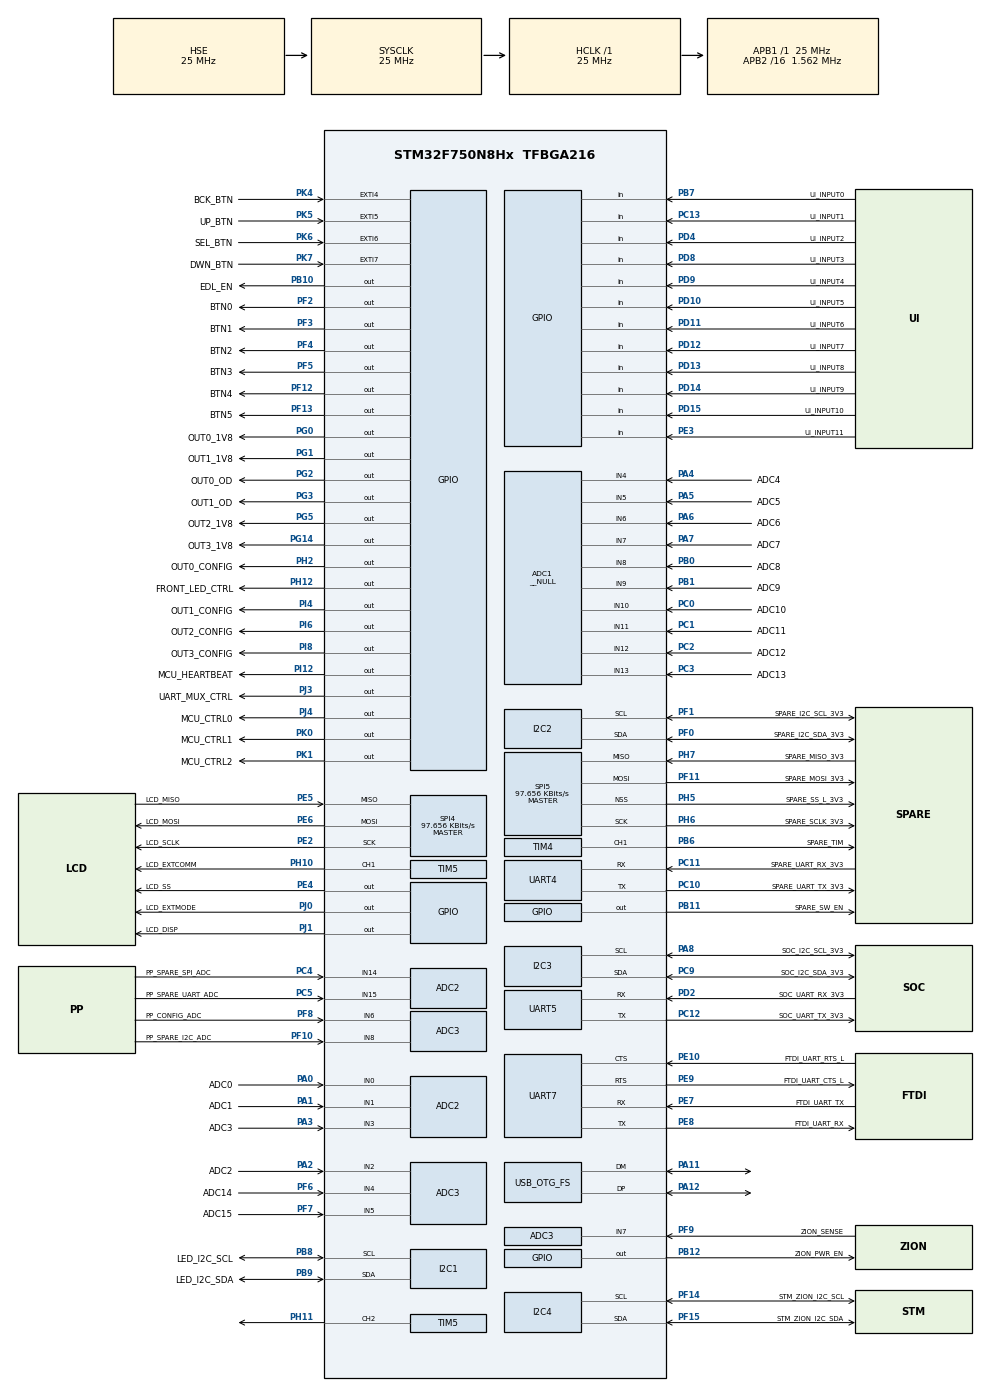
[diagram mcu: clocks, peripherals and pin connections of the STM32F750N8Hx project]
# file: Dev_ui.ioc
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ADC1.Channel-0\#ChannelRegularConversion=ADC_CHANNEL_3
ADC1.Channel-1\#ChannelRegularConversion=ADC_CHANNEL_4
ADC1.Channel-10\#ChannelRegularConversion=ADC_CHANNEL_13
ADC1.Channel-2\#ChannelRegularConversion=ADC_CHANNEL_5
ADC1.Channel-3\#ChannelRegularConversion=ADC_CHANNEL_6
ADC1.Channel-4\#ChannelRegularConversion=ADC_CHANNEL_7
ADC1.Channel-5\#ChannelRegularConversion=ADC_CHANNEL_8
ADC1.Channel-6\#ChannelRegularConversion=ADC_CHANNEL_9
ADC1.Channel-7\#ChannelRegularConversion=ADC_CHANNEL_10
ADC1.Channel-8\#ChannelRegularConversion=ADC_CHANNEL_11
ADC1.Channel-9\#ChannelRegularConversion=ADC_CHANNEL_12
ADC1.ContinuousConvMode=ENABLE
ADC1.DMAContinuousRequests=ENABLE
ADC1.InjNumberOfConversion=0
ADC1.Mode=__NULL
ADC1.NbrOfConversion=11
ADC1.NbrOfConversionFlag=1
ADC1.Rank-0\#ChannelRegularConversion=1
ADC1.Rank-1\#ChannelRegularConversion=2
ADC1.Rank-10\#ChannelRegularConversion=11
ADC1.Rank-2\#ChannelRegularConversion=3
ADC1.Rank-3\#ChannelRegularConversion=4
ADC1.Rank-4\#ChannelRegularConversion=5
ADC1.Rank-5\#ChannelRegularConversion=6
ADC1.Rank-6\#ChannelRegularConversion=7
ADC1.Rank-7\#ChannelRegularConversion=8
ADC1.Rank-8\#ChannelRegularConversion=9
ADC1.Rank-9\#ChannelRegularConversion=10
ADC1.SamplingTime-0\#ChannelRegularConversion=ADC_SAMPLETIME_480CYCLES
ADC1.SamplingTime-1\#ChannelRegularConversion=ADC_SAMPLETIME_480CYCLES
ADC1.SamplingTime-10\#ChannelRegularConversion=ADC_SAMPLETIME_480CYCLES
ADC1.SamplingTime-2\#ChannelRegularConversion=ADC_SAMPLETIME_480CYCLES
ADC1.SamplingTime-3\#ChannelRegularConversion=ADC_SAMPLETIME_480CYCLES
ADC1.SamplingTime-4\#ChannelRegularConversion=ADC_SAMPLETIME_480CYCLES
ADC1.SamplingTime-5\#ChannelRegularConversion=ADC_SAMPLETIME_480CYCLES
ADC1.SamplingTime-6\#ChannelRegularConversion=ADC_SAMPLETIME_480CYCLES
ADC1.SamplingTime-7\#ChannelRegularConversion=ADC_SAMPLETIME_480CYCLES
ADC1.SamplingTime-8\#ChannelRegularConversion=ADC_SAMPLETIME_480CYCLES
ADC1.SamplingTime-9\#ChannelRegularConversion=ADC_SAMPLETIME_480CYCLES
ADC1.ScanConvMode=ADC_SCAN_ENABLE
ADC1.master=1
ADC2.Channel-0\#ChannelRegularConversion=ADC_CHANNEL_0
ADC2.Channel-1\#ChannelRegularConversion=ADC_CHANNEL_1
ADC2.Channel-2\#ChannelRegularConversion=ADC_CHANNEL_14
ADC2.Channel-3\#ChannelRegularConversion=ADC_CHANNEL_15
ADC2.ContinuousConvMode=ENABLE
ADC2.DMAContinuousRequests=ENABLE
ADC2.NbrOfConversion=4
ADC2.NbrOfConversionFlag=1
ADC2.Rank-0\#ChannelRegularConversion=1
ADC2.Rank-1\#ChannelRegularConversion=2
ADC2.Rank-2\#ChannelRegularConversion=3
ADC2.Rank-3\#ChannelRegularConversion=4
ADC2.SamplingTime-0\#ChannelRegularConversion=ADC_SAMPLETIME_480CYCLES
ADC2.SamplingTime-1\#ChannelRegularConversion=ADC_SAMPLETIME_480CYCLES
ADC2.SamplingTime-2\#ChannelRegularConversion=ADC_SAMPLETIME_480CYCLES
ADC2.SamplingTime-3\#ChannelRegularConversion=ADC_SAMPLETIME_480CYCLES
ADC2.ScanConvMode=ADC_SCAN_ENABLE
ADC3.Channel-0\#ChannelRegularConversion=ADC_CHANNEL_2
ADC3.Channel-1\#ChannelRegularConversion=ADC_CHANNEL_4
ADC3.Channel-2\#ChannelRegularConversion=ADC_CHANNEL_5
ADC3.Channel-3\#ChannelRegularConversion=ADC_CHANNEL_6
ADC3.Channel-4\#ChannelRegularConversion=ADC_CHANNEL_7
ADC3.Channel-5\#ChannelRegularConversion=ADC_CHANNEL_8
ADC3.ContinuousConvMode=ENABLE
ADC3.DMAContinuousRequests=ENABLE
ADC3.NbrOfConversion=6
ADC3.NbrOfConversionFlag=1
ADC3.Rank-0\#ChannelRegularConversion=1
ADC3.Rank-1\#ChannelRegularConversion=2
ADC3.Rank-2\#ChannelRegularConversion=3
ADC3.Rank-3\#ChannelRegularConversion=4
ADC3.Rank-4\#ChannelRegularConversion=5
ADC3.Rank-5\#ChannelRegularConversion=6
ADC3.SamplingTime-0\#ChannelRegularConversion=ADC_SAMPLETIME_480CYCLES
ADC3.SamplingTime-1\#ChannelRegularConversion=ADC_SAMPLETIME_480CYCLES
ADC3.SamplingTime-2\#ChannelRegularConversion=ADC_SAMPLETIME_480CYCLES
ADC3.SamplingTime-3\#ChannelRegularConversion=ADC_SAMPLETIME_480CYCLES
ADC3.SamplingTime-4\#ChannelRegularConversion=ADC_SAMPLETIME_480CYCLES
ADC3.SamplingTime-5\#ChannelRegularConversion=ADC_SAMPLETIME_480CYCLES
ADC3.ScanConvMode=ADC_SCAN_ENABLE
ADC3.TwoSamplingDelay=ADC_TWOSAMPLINGDELAY_20CYCLES
Dma.ADC1.0.Direction=DMA_PERIPH_TO_MEMORY
Dma.ADC1.0.FIFOMode=DMA_FIFOMODE_DISABLE
Dma.ADC1.0.Instance=DMA2_Stream0
Dma.ADC1.0.MemDataAlignment=DMA_MDATAALIGN_WORD
Dma.ADC1.0.MemInc=DMA_MINC_ENABLE
Dma.ADC1.0.Mode=DMA_NORMAL
Dma.ADC1.0.PeriphDataAlignment=DMA_PDATAALIGN_WORD
Dma.ADC1.0.PeriphInc=DMA_PINC_DISABLE
Dma.ADC1.0.Priority=DMA_PRIORITY_LOW
Dma.ADC2.1.Direction=DMA_PERIPH_TO_MEMORY
Dma.ADC2.1.FIFOMode=DMA_FIFOMODE_DISABLE
Dma.ADC2.1.Instance=DMA2_Stream2
Dma.ADC2.1.MemDataAlignment=DMA_MDATAALIGN_WORD
Dma.ADC2.1.MemInc=DMA_MINC_ENABLE
Dma.ADC2.1.Mode=DMA_NORMAL
Dma.ADC2.1.PeriphDataAlignment=DMA_PDATAALIGN_WORD
Dma.ADC2.1.PeriphInc=DMA_PINC_DISABLE
Dma.ADC2.1.Priority=DMA_PRIORITY_LOW
Dma.ADC3.2.Direction=DMA_PERIPH_TO_MEMORY
Dma.ADC3.2.FIFOMode=DMA_FIFOMODE_DISABLE
Dma.ADC3.2.Instance=DMA2_Stream1
Dma.ADC3.2.MemDataAlignment=DMA_MDATAALIGN_WORD
Dma.ADC3.2.MemInc=DMA_MINC_ENABLE
Dma.ADC3.2.Mode=DMA_NORMAL
Dma.ADC3.2.PeriphDataAlignment=DMA_PDATAALIGN_WORD
Dma.ADC3.2.PeriphInc=DMA_PINC_DISABLE
Dma.ADC3.2.Priority=DMA_PRIORITY_LOW
Dma.Request0=ADC1
Dma.Request1=ADC2
Dma.Request2=ADC3
Dma.Request3=UART5_RX
Dma.UART5_RX.3.Direction=DMA_PERIPH_TO_MEMORY
Dma.UART5_RX.3.FIFOMode=DMA_FIFOMODE_DISABLE
Dma.UART5_RX.3.Instance=DMA1_Stream0
Dma.UART5_RX.3.MemDataAlignment=DMA_MDATAALIGN_BYTE
Dma.UART5_RX.3.MemInc=DMA_MINC_ENABLE
Dma.UART5_RX.3.Mode=DMA_CIRCULAR
Dma.UART5_RX.3.PeriphDataAlignment=DMA_PDATAALIGN_BYTE
Dma.UART5_RX.3.PeriphInc=DMA_PINC_DISABLE
Dma.UART5_RX.3.Priority=DMA_PRIORITY_LOW
FREERTOS.Tasks01=Heartbeat,8,128,startHeartbeat,Default,NULL,Dynamic,NULL,NULL;adcRead,9,128,startADCRead,Default,NULL,Dynamic,NULL,NULL;DatScreenBlink,24,1000,GetDaScreenBlink,Default,NULL,Dynamic,NULL,NULL;Navigation,40,128,navigation_control,Default,NULL,Dynamic,NULL,NULL
I2C1.Timing=0x00606092
I2C2.Timing=0x00606092
I2C3.Timing=0x00606092
I2C4.Timing=0x00606092
Mcu.Family=STM32F7
Mcu.Name=STM32F750N8Hx
Mcu.Package=TFBGA216
NVIC.ADC_IRQn=true\:5\:0\:false\:false\:true\:true\:true\:true
NVIC.DMA1_Stream0_IRQn=true\:5\:0\:false\:false\:true\:true\:false\:true
NVIC.DMA2_Stream0_IRQn=true\:5\:0\:false\:false\:true\:true\:false\:true
NVIC.DMA2_Stream1_IRQn=true\:5\:0\:false\:false\:true\:true\:false\:true
NVIC.DMA2_Stream2_IRQn=true\:5\:0\:false\:false\:true\:true\:false\:true
NVIC.EXTI4_IRQn=true\:5\:0\:false\:true\:true\:2\:true\:true\:true
NVIC.EXTI9_5_IRQn=true\:5\:0\:false\:true\:true\:1\:true\:true\:true
NVIC.PriorityGroup=NVIC_PRIORITYGROUP_4
NVIC.SPI4_IRQn=true\:5\:0\:false\:false\:true\:true\:true\:true
NVIC.TIM6_DAC_IRQn=true\:0\:0\:false\:false\:true\:false\:false\:true
NVIC.TimeBase=TIM6_DAC_IRQn
NVIC.TimeBaseIP=TIM6
PA0/WKUP.GPIO_Label=ADC0
PA0/WKUP.Signal=ADCx_IN0
PA1.GPIO_Label=ADC1
PA1.Signal=ADCx_IN1
PA10.Signal=USB_OTG_FS_ID
PA11.Mode=Device_Only
PA11.Signal=USB_OTG_FS_DM
PA12.Mode=Device_Only
PA12.Signal=USB_OTG_FS_DP
PA13.Mode=JTAG_5_pins
PA13.Signal=SYS_JTMS-SWDIO
PA14.Mode=JTAG_5_pins
PA14.Signal=SYS_JTCK-SWCLK
PA15.Mode=JTAG_5_pins
PA15.Signal=SYS_JTDI
PA2.GPIO_Label=ADC2
PA2.Signal=ADCx_IN2
PA3.GPIO_Label=ADC3
PA3.GPIO_Mode=GPIO_MODE_ANALOG
PA3.GPIO_PuPd=GPIO_NOPULL
PA3.Signal=ADCx_IN3
PA4.GPIO_Label=ADC4
PA4.GPIO_Mode=GPIO_MODE_ANALOG
PA4.GPIO_PuPd=GPIO_NOPULL
PA4.Signal=SharedAnalog_PA4
PA5.GPIO_Label=ADC5
PA5.GPIO_Mode=GPIO_MODE_ANALOG
PA5.GPIO_PuPd=GPIO_NOPULL
PA5.Signal=SharedAnalog_PA5
PA6.GPIO_Label=ADC6
PA6.GPIO_Mode=GPIO_MODE_ANALOG
PA6.GPIO_PuPd=GPIO_NOPULL
PA6.Signal=ADCx_IN6
PA7.GPIO_Label=ADC7
PA7.Signal=ADCx_IN7
PA8.GPIO_Label=SOC_I2C_SCL_3V3
PA8.GPIO_Mode=GPIO_MODE_AF_OD
PA8.GPIO_PuPdOD=GPIO_PULLUP
PA8.GPIO_Speed=GPIO_SPEED_FREQ_VERY_HIGH
PA8.Mode=I2C
PA8.Signal=I2C3_SCL
PB0.GPIO_Label=ADC8
PB0.Signal=ADCx_IN8
PB1.GPIO_Label=ADC9
PB1.GPIO_Mode=GPIO_MODE_ANALOG
PB1.GPIO_PuPd=GPIO_NOPULL
PB1.Signal=ADCx_IN9
PB10.GPIO_Label=EDL_EN
PB10.Signal=GPIO_Output
PB11.GPIO_Label=SPARE_SW_EN
PB11.Signal=GPIO_Output
PB12.GPIO_Label=ZION_PWR_EN
PB12.Signal=GPIO_Output
PB3.Mode=JTAG_5_pins
PB3.Signal=SYS_JTDO-SWO
PB4.Mode=JTAG_5_pins
PB4.Signal=SYS_JTRST
PB6.GPIO_Label=SPARE_TIM
PB6.Signal=S_TIM4_CH1
PB7.GPIO_Label=UI_INPUT0
PB7.GPIO_Mode=GPIO_MODE_INPUT
PB7.GPIO_PuPd=GPIO_NOPULL
PB7.Signal=GPIO_Input
PB8.GPIO_Label=LED_I2C_SCL
PB8.GPIO_Mode=GPIO_MODE_AF_OD
PB8.GPIO_PuPdOD=GPIO_PULLUP
PB8.GPIO_Speed=GPIO_SPEED_FREQ_VERY_HIGH
PB8.Mode=I2C
PB8.Signal=I2C1_SCL
PB9.GPIO_Label=LED_I2C_SDA
PB9.GPIO_Mode=GPIO_MODE_AF_OD
PB9.GPIO_PuPdOD=GPIO_PULLUP
PB9.GPIO_Speed=GPIO_SPEED_FREQ_VERY_HIGH
PB9.Mode=I2C
PB9.Signal=I2C1_SDA
PC0.GPIO_Label=ADC10
PC0.GPIO_Mode=GPIO_MODE_ANALOG
PC0.GPIO_PuPd=GPIO_NOPULL
PC0.Signal=ADCx_IN10
PC1.GPIO_Label=ADC11
PC1.Signal=ADCx_IN11
PC10.GPIO_Label=SPARE_UART_TX_3V3
PC10.GPIO_ModeDefaultPP=GPIO_MODE_AF_PP
PC10.GPIO_PuPd=GPIO_NOPULL
PC10.GPIO_Speed=GPIO_SPEED_FREQ_VERY_HIGH
PC10.Mode=Asynchronous
PC10.Signal=UART4_TX
PC11.GPIO_Label=SPARE_UART_RX_3V3
PC11.GPIO_ModeDefaultPP=GPIO_MODE_AF_PP
PC11.GPIO_PuPd=GPIO_NOPULL
PC11.GPIO_Speed=GPIO_SPEED_FREQ_VERY_HIGH
PC11.Mode=Asynchronous
PC11.Signal=UART4_RX
PC12.GPIO_Label=SOC_UART_TX_3V3
PC12.GPIO_ModeDefaultPP=GPIO_MODE_AF_PP
PC12.GPIO_PuPd=GPIO_NOPULL
PC12.GPIO_Speed=GPIO_SPEED_FREQ_VERY_HIGH
PC12.Mode=Asynchronous
PC12.Signal=UART5_TX
PC13.GPIO_Label=UI_INPUT1
PC13.GPIO_Mode=GPIO_MODE_INPUT
PC13.GPIO_PuPd=GPIO_NOPULL
PC13.Signal=GPIO_Input
PC14/OSC32_IN.Mode=LSE-External-Oscillator
PC14/OSC32_IN.Signal=RCC_OSC32_IN
PC15/OSC32_OUT.Mode=LSE-External-Oscillator
PC15/OSC32_OUT.Signal=RCC_OSC32_OUT
PC2.GPIO_Label=ADC12
PC2.GPIO_Mode=GPIO_MODE_ANALOG
PC2.GPIO_PuPd=GPIO_NOPULL
PC2.Signal=ADCx_IN12
PC3.GPIO_Label=ADC13
PC3.GPIO_Mode=GPIO_MODE_ANALOG
PC3.GPIO_PuPd=GPIO_NOPULL
PC3.Signal=ADCx_IN13
PC4.GPIO_Label=PP_SPARE_SPI_ADC
PC4.Signal=ADCx_IN14
PC5.GPIO_Label=PP_SPARE_UART_ADC
PC5.Signal=ADCx_IN15
PC9.GPIO_Label=SOC_I2C_SDA_3V3
PC9.GPIO_Mode=GPIO_MODE_AF_OD
PC9.GPIO_PuPdOD=GPIO_PULLUP
PC9.GPIO_Speed=GPIO_SPEED_FREQ_VERY_HIGH
PC9.Mode=I2C
PC9.Signal=I2C3_SDA
PD10.GPIO_Label=UI_INPUT5
PD10.GPIO_Mode=GPIO_MODE_INPUT
PD10.GPIO_PuPd=GPIO_NOPULL
PD10.Signal=GPIO_Input
PD11.GPIO_Label=UI_INPUT6
PD11.GPIO_Mode=GPIO_MODE_INPUT
PD11.GPIO_PuPd=GPIO_NOPULL
PD11.Signal=GPIO_Input
PD12.GPIO_Label=UI_INPUT7
PD12.GPIO_Mode=GPIO_MODE_INPUT
PD12.GPIO_PuPd=GPIO_NOPULL
PD12.Signal=GPIO_Input
PD13.GPIO_Label=UI_INPUT8
PD13.GPIO_Mode=GPIO_MODE_INPUT
PD13.GPIO_PuPd=GPIO_NOPULL
PD13.Signal=GPIO_Input
PD14.GPIO_Label=UI_INPUT9
PD14.GPIO_Mode=GPIO_MODE_INPUT
PD14.GPIO_PuPd=GPIO_NOPULL
PD14.Signal=GPIO_Input
PD15.GPIO_Label=UI_INPUT10
PD15.GPIO_Mode=GPIO_MODE_INPUT
PD15.GPIO_PuPd=GPIO_NOPULL
PD15.Signal=GPIO_Input
PD2.GPIO_Label=SOC_UART_RX_3V3
PD2.GPIO_ModeDefaultPP=GPIO_MODE_AF_PP
PD2.GPIO_PuPd=GPIO_NOPULL
PD2.GPIO_Speed=GPIO_SPEED_FREQ_VERY_HIGH
PD2.Mode=Asynchronous
PD2.Signal=UART5_RX
PD4.GPIO_Label=UI_INPUT2
PD4.GPIO_Mode=GPIO_MODE_INPUT
PD4.GPIO_PuPd=GPIO_NOPULL
PD4.Signal=GPIO_Input
PD8.GPIO_Label=UI_INPUT3
PD8.GPIO_Mode=GPIO_MODE_INPUT
PD8.GPIO_PuPd=GPIO_NOPULL
PD8.Signal=GPIO_Input
PD9.GPIO_Label=UI_INPUT4
PD9.GPIO_Mode=GPIO_MODE_INPUT
PD9.GPIO_PuPd=GPIO_NOPULL
PD9.Signal=GPIO_Input
PE10.GPIO_Label=FTDI_UART_RTS_L
PE10.GPIO_Mode=GPIO_MODE_AF_PP
PE10.GPIO_PuPd=GPIO_NOPULL
PE10.GPIO_Speed=GPIO_SPEED_FREQ_VERY_HIGH
PE10.Mode=CTS_RTS
PE10.Signal=UART7_CTS
PE2.GPIO_Label=LCD_SCLK
PE2.GPIO_Mode=GPIO_MODE_AF_PP
PE2.GPIO_PuPd=GPIO_NOPULL
PE2.GPIO_Speed=GPIO_SPEED_FREQ_VERY_HIGH
PE2.Mode=Full_Duplex_Master
PE2.Signal=SPI4_SCK
PE3.GPIO_Label=UI_INPUT11
PE3.GPIO_Mode=GPIO_MODE_INPUT
PE3.GPIO_PuPd=GPIO_NOPULL
PE3.Signal=GPIO_Input
PE4.GPIO_Label=LCD_SS
PE4.GPIO_Speed=GPIO_SPEED_FREQ_HIGH
PE4.Signal=GPIO_Output
PE5.GPIO_Label=LCD_MISO
PE5.GPIO_Mode=GPIO_MODE_AF_PP
PE5.GPIO_PuPd=GPIO_NOPULL
PE5.GPIO_Speed=GPIO_SPEED_FREQ_VERY_HIGH
PE5.Mode=Full_Duplex_Master
PE5.Signal=SPI4_MISO
PE6.GPIO_Label=LCD_MOSI
PE6.GPIO_Mode=GPIO_MODE_AF_PP
PE6.GPIO_PuPd=GPIO_NOPULL
PE6.GPIO_Speed=GPIO_SPEED_FREQ_VERY_HIGH
PE6.Mode=Full_Duplex_Master
PE6.Signal=SPI4_MOSI
PE7.GPIO_Label=FTDI_UART_TX
PE7.GPIO_ModeDefaultPP=GPIO_MODE_AF_PP
PE7.GPIO_PuPd=GPIO_NOPULL
PE7.GPIO_Speed=GPIO_SPEED_FREQ_VERY_HIGH
PE7.Mode=Asynchronous
PE7.Signal=UART7_RX
PE8.GPIO_Label=FTDI_UART_RX
PE8.GPIO_ModeDefaultPP=GPIO_MODE_AF_PP
PE8.GPIO_PuPd=GPIO_NOPULL
PE8.GPIO_Speed=GPIO_SPEED_FREQ_VERY_HIGH
PE8.Mode=Asynchronous
PE8.Signal=UART7_TX
PE9.GPIO_Label=FTDI_UART_CTS_L
PE9.GPIO_Mode=GPIO_MODE_AF_PP
PE9.GPIO_PuPd=GPIO_NOPULL
PE9.GPIO_Speed=GPIO_SPEED_FREQ_VERY_HIGH
PE9.Mode=CTS_RTS
PE9.Signal=UART7_RTS
PF0.GPIO_Label=SPARE_I2C_SDA_3V3
PF0.GPIO_Mode=GPIO_MODE_AF_OD
PF0.GPIO_PuPdOD=GPIO_PULLUP
PF0.GPIO_Speed=GPIO_SPEED_FREQ_VERY_HIGH
PF0.Mode=I2C
PF0.Signal=I2C2_SDA
PF1.GPIO_Label=SPARE_I2C_SCL_3V3
PF1.GPIO_Mode=GPIO_MODE_AF_OD
PF1.GPIO_PuPdOD=GPIO_PULLUP
PF1.GPIO_Speed=GPIO_SPEED_FREQ_VERY_HIGH
PF1.Mode=I2C
PF1.Signal=I2C2_SCL
PF10.GPIO_Label=PP_SPARE_I2C_ADC
PF10.Mode=IN8
PF10.Signal=ADC3_IN8
PF11.GPIO_Label=SPARE_MOSI_3V3
PF11.GPIO_Mode=GPIO_MODE_AF_PP
PF11.GPIO_PuPd=GPIO_NOPULL
PF11.GPIO_Speed=GPIO_SPEED_FREQ_VERY_HIGH
PF11.Mode=Full_Duplex_Master
PF11.Signal=SPI5_MOSI
PF12.GPIO_Label=BTN4
PF12.GPIO_ModeDefaultOutputPP=GPIO_MODE_OUTPUT_PP
PF12.GPIO_PuPd=GPIO_NOPULL
PF12.GPIO_Speed=GPIO_SPEED_FREQ_LOW
PF12.PinState=GPIO_PIN_RESET
PF12.Signal=GPIO_Output
PF13.GPIO_Label=BTN5
PF13.GPIO_ModeDefaultOutputPP=GPIO_MODE_OUTPUT_PP
PF13.GPIO_PuPd=GPIO_NOPULL
PF13.GPIO_Speed=GPIO_SPEED_FREQ_LOW
PF13.PinState=GPIO_PIN_RESET
PF13.Signal=GPIO_Output
PF14.GPIO_Label=STM_ZION_I2C_SCL
PF14.GPIO_Mode=GPIO_MODE_AF_OD
PF14.GPIO_PuPdOD=GPIO_PULLUP
PF14.GPIO_Speed=GPIO_SPEED_FREQ_VERY_HIGH
PF14.Mode=I2C
PF14.Signal=I2C4_SCL
PF15.GPIO_Label=STM_ZION_I2C_SDA
PF15.GPIO_Mode=GPIO_MODE_AF_OD
PF15.GPIO_PuPdOD=GPIO_PULLUP
PF15.GPIO_Speed=GPIO_SPEED_FREQ_VERY_HIGH
PF15.Mode=I2C
PF15.Signal=I2C4_SDA
PF2.GPIO_Label=BTN0
PF2.GPIO_ModeDefaultOutputPP=GPIO_MODE_OUTPUT_PP
PF2.GPIO_PuPd=GPIO_NOPULL
PF2.GPIO_Speed=GPIO_SPEED_FREQ_LOW
PF2.PinState=GPIO_PIN_RESET
PF2.Signal=GPIO_Output
PF3.GPIO_Label=BTN1
PF3.GPIO_ModeDefaultOutputPP=GPIO_MODE_OUTPUT_PP
PF3.GPIO_PuPd=GPIO_NOPULL
PF3.GPIO_Speed=GPIO_SPEED_FREQ_LOW
PF3.PinState=GPIO_PIN_RESET
PF3.Signal=GPIO_Output
PF4.GPIO_Label=BTN2
PF4.GPIO_ModeDefaultOutputPP=GPIO_MODE_OUTPUT_PP
PF4.GPIO_PuPd=GPIO_NOPULL
PF4.GPIO_Speed=GPIO_SPEED_FREQ_LOW
PF4.PinState=GPIO_PIN_RESET
PF4.Signal=GPIO_Output
PF5.GPIO_Label=BTN3
PF5.GPIO_ModeDefaultOutputPP=GPIO_MODE_OUTPUT_PP
PF5.GPIO_PuPd=GPIO_NOPULL
PF5.GPIO_Speed=GPIO_SPEED_FREQ_LOW
PF5.PinState=GPIO_PIN_RESET
PF5.Signal=GPIO_Output
PF6.GPIO_Label=ADC14
PF6.GPIO_Mode=GPIO_MODE_ANALOG
PF6.GPIO_PuPd=GPIO_NOPULL
PF6.Mode=IN4
PF6.Signal=ADC3_IN4
PF7.GPIO_Label=ADC15
PF7.GPIO_Mode=GPIO_MODE_ANALOG
PF7.GPIO_PuPd=GPIO_NOPULL
PF7.Mode=IN5
PF7.Signal=ADC3_IN5
PF8.GPIO_Label=PP_CONFIG_ADC
PF8.GPIO_Mode=GPIO_MODE_ANALOG
PF8.GPIO_PuPd=GPIO_NOPULL
PF8.Mode=IN6
PF8.Signal=ADC3_IN6
PF9.GPIO_Label=ZION_SENSE
PF9.GPIO_Mode=GPIO_MODE_ANALOG
PF9.GPIO_PuPd=GPIO_NOPULL
PF9.Mode=IN7
PF9.Signal=ADC3_IN7
PG0.GPIO_Label=OUT0_1V8
PG0.GPIO_ModeDefaultOutputPP=GPIO_MODE_OUTPUT_PP
PG0.GPIO_PuPd=GPIO_NOPULL
PG0.GPIO_Speed=GPIO_SPEED_FREQ_LOW
PG0.PinState=GPIO_PIN_RESET
PG0.Signal=GPIO_Output
PG1.GPIO_Label=OUT1_1V8
PG1.GPIO_ModeDefaultOutputPP=GPIO_MODE_OUTPUT_PP
PG1.GPIO_PuPd=GPIO_NOPULL
PG1.GPIO_Speed=GPIO_SPEED_FREQ_LOW
PG1.PinState=GPIO_PIN_RESET
PG1.Signal=GPIO_Output
PG14.GPIO_Label=OUT3_1V8
PG14.GPIO_ModeDefaultOutputPP=GPIO_MODE_OUTPUT_PP
PG14.GPIO_PuPd=GPIO_NOPULL
PG14.GPIO_Speed=GPIO_SPEED_FREQ_LOW
PG14.PinState=GPIO_PIN_RESET
PG14.Signal=GPIO_Output
PG2.GPIO_Label=OUT0_OD
PG2.Signal=GPIO_Output
PG3.GPIO_Label=OUT1_OD
PG3.Signal=GPIO_Output
PG5.GPIO_Label=OUT2_1V8
PG5.GPIO_ModeDefaultOutputPP=GPIO_MODE_OUTPUT_PP
PG5.GPIO_PuPd=GPIO_NOPULL
PG5.GPIO_Speed=GPIO_SPEED_FREQ_LOW
PG5.PinState=GPIO_PIN_RESET
PG5.Signal=GPIO_Output
PH0/OSC_IN.Mode=HSE-External-Oscillator
PH0/OSC_IN.Signal=RCC_OSC_IN
PH1/OSC_OUT.Mode=HSE-External-Oscillator
PH1/OSC_OUT.Signal=RCC_OSC_OUT
PH10.GPIO_Label=LCD_EXTCOMM
PH10.Signal=S_TIM5_CH1
PH11.Signal=S_TIM5_CH2
PH12.GPIO_Label=FRONT_LED_CTRL
PH12.Signal=GPIO_Output
PH2.GPIO_Label=OUT0_CONFIG
PH2.GPIO_ModeDefaultOutputPP=GPIO_MODE_OUTPUT_PP
PH2.GPIO_PuPd=GPIO_NOPULL
PH2.GPIO_Speed=GPIO_SPEED_FREQ_LOW
PH2.PinState=GPIO_PIN_RESET
PH2.Signal=GPIO_Output
PH5.GPIO_Label=SPARE_SS_L_3V3
PH5.GPIO_Mode=GPIO_MODE_AF_PP
PH5.GPIO_PuPd=GPIO_NOPULL
PH5.GPIO_Speed=GPIO_SPEED_FREQ_VERY_HIGH
PH5.Mode=NSS_Signal_Hard_Output
PH5.Signal=SPI5_NSS
PH6.GPIO_Label=SPARE_SCLK_3V3
PH6.GPIO_Mode=GPIO_MODE_AF_PP
PH6.GPIO_PuPd=GPIO_NOPULL
PH6.GPIO_Speed=GPIO_SPEED_FREQ_VERY_HIGH
PH6.Mode=Full_Duplex_Master
PH6.Signal=SPI5_SCK
PH7.GPIO_Label=SPARE_MISO_3V3
PH7.GPIO_Mode=GPIO_MODE_AF_PP
PH7.GPIO_PuPd=GPIO_NOPULL
PH7.GPIO_Speed=GPIO_SPEED_FREQ_VERY_HIGH
PH7.Mode=Full_Duplex_Master
PH7.Signal=SPI5_MISO
PI12.GPIO_Label=MCU_HEARTBEAT
PI12.GPIO_ModeDefaultOutputPP=GPIO_MODE_OUTPUT_PP
PI12.GPIO_PuPd=GPIO_NOPULL
PI12.GPIO_Speed=GPIO_SPEED_FREQ_LOW
PI12.PinState=GPIO_PIN_RESET
PI12.Signal=GPIO_Output
PI4.GPIO_Label=OUT1_CONFIG
PI4.GPIO_ModeDefaultOutputPP=GPIO_MODE_OUTPUT_PP
PI4.GPIO_PuPd=GPIO_NOPULL
PI4.GPIO_Speed=GPIO_SPEED_FREQ_LOW
PI4.PinState=GPIO_PIN_RESET
PI4.Signal=GPIO_Output
PI6.GPIO_Label=OUT2_CONFIG
PI6.GPIO_ModeDefaultOutputPP=GPIO_MODE_OUTPUT_PP
PI6.GPIO_PuPd=GPIO_NOPULL
PI6.GPIO_Speed=GPIO_SPEED_FREQ_LOW
PI6.PinState=GPIO_PIN_RESET
PI6.Signal=GPIO_Output
PI8.GPIO_Label=OUT3_CONFIG
PI8.GPIO_ModeDefaultOutputPP=GPIO_MODE_OUTPUT_PP
PI8.GPIO_PuPd=GPIO_NOPULL
PI8.GPIO_Speed=GPIO_SPEED_FREQ_LOW
PI8.PinState=GPIO_PIN_RESET
PI8.Signal=GPIO_Output
PJ0.GPIO_Label=LCD_EXTMODE
PJ0.GPIO_ModeDefaultOutputPP=GPIO_MODE_OUTPUT_PP
PJ0.GPIO_PuPd=GPIO_NOPULL
PJ0.GPIO_Speed=GPIO_SPEED_FREQ_LOW
PJ0.PinState=GPIO_PIN_RESET
PJ0.Signal=GPIO_Output
PJ1.GPIO_Label=LCD_DISP
PJ1.GPIO_ModeDefaultOutputPP=GPIO_MODE_OUTPUT_PP
PJ1.GPIO_PuPd=GPIO_NOPULL
PJ1.GPIO_Speed=GPIO_SPEED_FREQ_LOW
PJ1.PinState=GPIO_PIN_RESET
PJ1.Signal=GPIO_Output
PJ3.GPIO_Label=UART_MUX_CTRL
PJ3.GPIO_ModeDefaultOutputPP=GPIO_MODE_OUTPUT_PP
PJ3.GPIO_PuPd=GPIO_NOPULL
PJ3.GPIO_Speed=GPIO_SPEED_FREQ_LOW
PJ3.PinState=GPIO_PIN_RESET
PJ3.Signal=GPIO_Output
PJ4.GPIO_Label=MCU_CTRL0
PJ4.GPIO_ModeDefaultOutputPP=GPIO_MODE_OUTPUT_PP
PJ4.GPIO_PuPd=GPIO_NOPULL
PJ4.GPIO_Speed=GPIO_SPEED_FREQ_LOW
PJ4.PinState=GPIO_PIN_RESET
PJ4.Signal=GPIO_Output
PK0.GPIO_Label=MCU_CTRL1
PK0.GPIO_ModeDefaultOutputPP=GPIO_MODE_OUTPUT_PP
PK0.GPIO_PuPd=GPIO_NOPULL
PK0.GPIO_Speed=GPIO_SPEED_FREQ_LOW
PK0.PinState=GPIO_PIN_RESET
PK0.Signal=GPIO_Output
PK1.GPIO_Label=MCU_CTRL2
PK1.GPIO_ModeDefaultOutputPP=GPIO_MODE_OUTPUT_PP
PK1.GPIO_PuPd=GPIO_NOPULL
PK1.GPIO_Speed=GPIO_SPEED_FREQ_LOW
PK1.PinState=GPIO_PIN_RESET
PK1.Signal=GPIO_Output
PK4.GPIO_Label=BCK_BTN
PK4.GPIO_ModeDefaultEXTI=GPIO_MODE_IT_FALLING
PK4.Signal=GPXTI4
PK5.GPIO_Label=UP_BTN
PK5.GPIO_ModeDefaultEXTI=GPIO_MODE_IT_FALLING
PK5.Signal=GPXTI5
PK6.GPIO_Label=SEL_BTN
PK6.GPIO_ModeDefaultEXTI=GPIO_MODE_IT_FALLING
PK6.Signal=GPXTI6
PK7.GPIO_Label=DWN_BTN
PK7.GPIO_ModeDefaultEXTI=GPIO_MODE_IT_FALLING
PK7.Signal=GPXTI7
ProjectManager.HeapSize=0x200
ProjectManager.StackSize=0x400
ProjectManager.TargetToolchain=STM32CubeIDE
RCC.AHBFreq_Value=25000000
RCC.APB1Freq_Value=25000000
RCC.APB1TimFreq_Value=25000000
RCC.APB2CLKDivider=RCC_HCLK_DIV16
RCC.APB2Freq_Value=1562500
RCC.APB2TimFreq_Value=3125000
RCC.CortexFreq_Value=25000000
RCC.HCLKFreq_Value=25000000
RCC.HSE_VALUE=25000000
RCC.HSI_VALUE=16000000
RCC.PLLM=15
RCC.PLLN=144
RCC.PLLQ=5
RCC.PLLSAIN=60
RCC.RTCClockSelection=RCC_RTCCLKSOURCE_LSE
RCC.SYSCLKFreq_VALUE=25000000
RCC.SYSCLKSource=RCC_SYSCLKSOURCE_HSE
RCC.USBFreq_Value=48000000
RCC.VCOOutputFreq_Value=240000000
SH.ADCx_IN0.0=ADC2_IN0,IN0
SH.ADCx_IN1.0=ADC2_IN1,IN1
SH.ADCx_IN10.0=ADC1_IN10,IN10
SH.ADCx_IN10.1=ADC2_IN10,IN10
SH.ADCx_IN10.2=ADC3_IN10,IN10
SH.ADCx_IN11.0=ADC1_IN11,IN11
SH.ADCx_IN11.1=ADC2_IN11
SH.ADCx_IN11.2=ADC3_IN11
SH.ADCx_IN12.0=ADC1_IN12,IN12
SH.ADCx_IN12.1=ADC2_IN12,IN12
SH.ADCx_IN12.2=ADC3_IN12,IN12
SH.ADCx_IN13.0=ADC1_IN13,IN13
SH.ADCx_IN13.1=ADC2_IN13,IN13
SH.ADCx_IN13.2=ADC3_IN13,IN13
SH.ADCx_IN14.0=ADC2_IN14,IN14
SH.ADCx_IN15.0=ADC2_IN15,IN15
SH.ADCx_IN2.0=ADC3_IN2,IN2
SH.ADCx_IN3.0=ADC2_IN3,IN3
SH.ADCx_IN3.1=ADC3_IN3,IN3
SH.ADCx_IN3.2=ADC1_IN3,IN3
SH.ADCx_IN6.0=ADC1_IN6,IN6
SH.ADCx_IN6.1=ADC2_IN6,IN6
SH.ADCx_IN7.0=ADC1_IN7,IN7
SH.ADCx_IN8.0=ADC1_IN8,IN8
SH.ADCx_IN9.0=ADC1_IN9,IN9
SH.ADCx_IN9.1=ADC2_IN9,IN9
SH.S_TIM4_CH1.0=TIM4_CH1,PWM Generation1 CH1
SH.S_TIM5_CH1.0=TIM5_CH1,PWM Generation1 CH1
SH.S_TIM5_CH2.0=TIM5_CH2,PWM Generation2 CH2
SH.SharedAnalog_PA4.0=ADC1_IN4,IN4
SH.SharedAnalog_PA4.1=ADC2_IN4,IN4
SH.SharedAnalog_PA4.2=DAC_OUT1,DAC_OUT1
SH.SharedAnalog_PA5.0=ADC1_IN5,IN5
SH.SharedAnalog_PA5.1=ADC2_IN5,IN5
SH.SharedAnalog_PA5.2=DAC_OUT2,DAC_OUT2
SPI4.BaudRatePrescaler=SPI_BAUDRATEPRESCALER_16
SPI4.CalculateBaudRate=97.656 KBits/s
SPI4.DataSize=SPI_DATASIZE_16BIT
SPI4.Direction=SPI_DIRECTION_2LINES
SPI4.Mode=SPI_MODE_MASTER
SPI4.NSSPMode=SPI_NSS_PULSE_DISABLE
SPI4.VirtualType=VM_MASTER
SPI5.BaudRatePrescaler=SPI_BAUDRATEPRESCALER_16
SPI5.CalculateBaudRate=97.656 KBits/s
SPI5.DataSize=SPI_DATASIZE_8BIT
SPI5.Direction=SPI_DIRECTION_2LINES
SPI5.Mode=SPI_MODE_MASTER
SPI5.NSSPMode=SPI_NSS_PULSE_DISABLE
SPI5.VirtualNSS=VM_NSSHARD
SPI5.VirtualType=VM_MASTER
TIM4.Channel-PWM\ Generation1\ CH1=TIM_CHANNEL_1
TIM5.Channel-PWM\ Generation1\ CH1=TIM_CHANNEL_1
TIM5.Channel-PWM\ Generation2\ CH2=TIM_CHANNEL_2
USB_OTG_FS.VirtualMode=Device_Only
VP_FREERTOS_VS_CMSIS_V2.Mode=CMSIS_V2
VP_RTC_VS_RTC_Activate.Mode=RTC_Enabled
VP_RTC_VS_RTC_Calendar.Mode=RTC_Calendar
VP_SYS_VS_tim6.Mode=TIM6
VP_TIM4_VS_ClockSourceINT.Mode=Internal
VP_TIM5_VS_ClockSourceINT.Mode=Internal
board=custom

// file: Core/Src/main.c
/* USER CODE BEGIN Header */
/**
  ******************************************************************************
  * @file           : main.c
  * @brief          : Main program body
  ******************************************************************************
  * @attention
  *
  * <h2><center>&copy; Copyright (c) 2021 STMicroelectronics.
  * All rights reserved.</center></h2>
  *
  * This software component is licensed by ST under BSD 3-Clause license,
  * the "License"; You may not use this file except in compliance with the
  * License. You may obtain a copy of the License at:
  *                        opensource.org/licenses/BSD-3-Clause
  *
  ******************************************************************************
  */
/* USER CODE END Header */
#include "main.h"
#include "cmsis_os.h"

/* USER CODE BEGIN PTD */
#define ADC_BUF_LEN 5000
/* USER CODE END PTD */

ADC_HandleTypeDef hadc1;
ADC_HandleTypeDef hadc2;
ADC_HandleTypeDef hadc3;
DMA_HandleTypeDef hdma_adc1;
DMA_HandleTypeDef hdma_adc2;
DMA_HandleTypeDef hdma_adc3;

DAC_HandleTypeDef hdac;

I2C_HandleTypeDef hi2c1;
I2C_HandleTypeDef hi2c2;
I2C_HandleTypeDef hi2c3;
I2C_HandleTypeDef hi2c4;

RTC_HandleTypeDef hrtc;

SPI_HandleTypeDef hspi4;
SPI_HandleTypeDef hspi5;

TIM_HandleTypeDef htim4;
TIM_HandleTypeDef htim5;

UART_HandleTypeDef huart4;
UART_HandleTypeDef huart5;
UART_HandleTypeDef huart7;
DMA_HandleTypeDef hdma_uart5_rx;

PCD_HandleTypeDef hpcd_USB_OTG_FS;

/* Definitions for Heartbeat */
osThreadId_t HeartbeatHandle;
const osThreadAttr_t Heartbeat_attributes = {
  .name = "Heartbeat",
  .priority = (osPriority_t) osPriorityLow,
  .stack_size = 128 * 4
};
/* Definitions for adcRead */
osThreadId_t adcReadHandle;
const osThreadAttr_t adcRead_attributes = {
  .name = "adcRead",
  .priority = (osPriority_t) osPriorityLow1,
  .stack_size = 128 * 4
};
/* Definitions for DatScreenBlink */
osThreadId_t DatScreenBlinkHandle;
const osThreadAttr_t DatScreenBlink_attributes = {
  .name = "DatScreenBlink",
  .priority = (osPriority_t) osPriorityNormal,
  .stack_size = 1000 * 4
};
/* Definitions for Navigation */
osThreadId_t NavigationHandle;
const osThreadAttr_t Navigation_attributes = {
  .name = "Navigation",
  .priority = (osPriority_t) osPriorityHigh,
  .stack_size = 128 * 4
};
/* USER CODE BEGIN PV */
uint16_t adc1_buf[ADC_BUF_LEN];
uint16_t adc2_buf[ADC_BUF_LEN];
uint16_t adc3_buf[ADC_BUF_LEN];
uint8_t adcRestart[3];
uint8_t inputButtonSet = NO_BTN_PRESS; //set to a higher value than any other button priority. 5 is the "unused" state
/* USER CODE END PV */

void SystemClock_Config(void);
static void MX_GPIO_Init(void);
static void MX_DMA_Init(void);
static void MX_ADC1_Init(void);
static void MX_ADC2_Init(void);
static void MX_ADC3_Init(void);
static void MX_I2C1_Init(void);
static void MX_I2C2_Init(void);
static void MX_TIM4_Init(void);
static void MX_TIM5_Init(void);
static void MX_UART5_Init(void);
static void MX_I2C4_Init(void);
static void MX_RTC_Init(void);
static void MX_UART4_Init(void);
static void MX_UART7_Init(void);
static void MX_I2C3_Init(void);
static void MX_SPI4_Init(void);
static void MX_SPI5_Init(void);
static void MX_USB_OTG_FS_PCD_Init(void);
static void MX_DAC_Init(void);
void startHeartbeat(void *argument);
void startADCRead(void *argument);
void GetDaScreenBlink(void *argument);
void navigation_control(void *argument);

static void MX_NVIC_Init(void);
/* USER CODE BEGIN PFP */
void uartTransmitChar(char *message,int uart);
void uartTransmitInt(uint16_t *number, int uart);
uint8_t * readI2CRegister(uint8_t address, uint8_t reg, int bytes, int i2CBank);
int writeI2CRegister(uint8_t address, uint8_t reg, uint8_t * bytes, int numBytes, int i2CBank);
void setErrorLED(int led, _Bool change);
void configureLEDDriver();
/* USER CODE END PFP */

/* USER CODE BEGIN 0 */
struct LED{
	uint8_t address;
	uint8_t mode0_reg;
	uint8_t led0_reg;
	uint8_t led1_reg;
	uint8_t led2_reg;
	uint8_t led3_reg;
	uint8_t iref_reg;
	uint8_t mode0_oscon_value;
	uint8_t led7_pwm;
	uint8_t led8_pwm;
	uint8_t led9_pwm;
	uint8_t pwm;
	int i2cBank;
};
static struct LED LED = {0x60 << 1, 0x00, 0x14, 0x15, 0x16, 0x17, 0x1C,0x11,0x09,0x0A,0x0B, 0x22,1};
struct GPIOs{

};
/* USER CODE END 0 */

int main(void)
{
  /* USER CODE BEGIN 1 */
 char spi_buf[20];
 static uint16_t LCD_Blink_White = 0b0001100000000000;
 static uint16_t LCD_Blink_Black = 0b0001000000000000;
 static uint16_t LCD_Green = 0b0100010001000100;
 static uint16_t LCD_White = 0b1110111011101110;
 static uint16_t LCD_Red = 0b1000100010001000;
 static uint16_t update_Line1 = 0b1001000010010001;
 static uint16_t update_Line2 = 0b1001000010010011;
 static uint16_t update_Line3 = 0b1001000010010010;
 static uint16_t update_dummy = 0b0000000000000000;
 static uint16_t LCD_Clear = 0b0010000000000000;
 static _Bool ON = 1;
 static _Bool OFF = 0;
 char uartBuf[50];
 int uartBufLen;
 static const uint8_t LED_ADDR = 0x60 <<1;
 HAL_StatusTypeDef ret;
 uint8_t buf[12];
 int16_t val;

  /* USER CODE END 1 */

  /* MCU Configuration--------------------------------------------------------*/

  /* Reset of all peripherals, Initializes the Flash interface and the Systick. */
  HAL_Init();

  /* Configure the system clock */
  SystemClock_Config();

  /* Initialize all configured peripherals */
  MX_GPIO_Init();
  MX_DMA_Init();
  MX_ADC1_Init();
  MX_ADC2_Init();
  MX_ADC3_Init();
  MX_I2C1_Init();
  MX_I2C2_Init();
  MX_TIM4_Init();
  MX_TIM5_Init();
  MX_UART5_Init();
  MX_I2C4_Init();
  MX_RTC_Init();
  MX_UART4_Init();
  MX_UART7_Init();
  MX_I2C3_Init();
  MX_SPI4_Init();
  MX_SPI5_Init();
  MX_USB_OTG_FS_PCD_Init();
  MX_DAC_Init();

  /* Initialize interrupts */
  MX_NVIC_Init();
  /* USER CODE BEGIN 2 */
  //HAL_ADC_ConfigChannel();
  HAL_ADC_Start_DMA(&hadc1, (uint32_t*)adc1_buf, ADC_BUF_LEN);
  HAL_ADC_Start_DMA(&hadc2, (uint32_t*)adc2_buf, ADC_BUF_LEN);
  HAL_ADC_Start_DMA(&hadc3, (uint32_t*)adc3_buf, ADC_BUF_LEN);
  HAL_GPIO_WritePin(GPIOJ,LCD_DISP_Pin,GPIO_PIN_SET);
  HAL_GPIO_WritePin(GPIOJ,LCD_EXTMODE_Pin,GPIO_PIN_RESET);
  HAL_Delay(1);
  HAL_GPIO_WritePin(LCD_SS_GPIO_Port,LCD_SS_Pin,GPIO_PIN_SET);
  HAL_SPI_Transmit(&hspi4, (uint16_t *)&LCD_Clear, 1, 100);
  HAL_GPIO_WritePin(LCD_SS_GPIO_Port,LCD_SS_Pin,GPIO_PIN_RESET);
  HAL_Delay(1);
  int x=1;
  uint16_t test[102];
  test[0] = update_Line1;
  uartTransmitInt(test[0],7);
  while (x<101){
	test[x] = LCD_Green;
	x=x+1;
  }
  x=0;
  test[61] = update_dummy;
  uartTransmitInt(test,7);
  HAL_GPIO_WritePin(LCD_SS_GPIO_Port,LCD_SS_Pin,GPIO_PIN_SET);
  HAL_SPI_Transmit(&hspi4, (uint16_t *)test, 102, 100);
  HAL_GPIO_WritePin(LCD_SS_GPIO_Port,LCD_SS_Pin,GPIO_PIN_RESET);
  HAL_Delay(5);
  test[0]=update_Line2;
  uartTransmitInt(test[0],7);
  HAL_GPIO_WritePin(LCD_SS_GPIO_Port,LCD_SS_Pin,GPIO_PIN_SET);
  HAL_SPI_Transmit(&hspi4, (uint16_t *)test, 102, 100);
  HAL_GPIO_WritePin(LCD_SS_GPIO_Port,LCD_SS_Pin,GPIO_PIN_RESET);
  HAL_Delay(5);
  test[0]=update_Line3;
  uartTransmitInt(test[0],7);
  HAL_GPIO_WritePin(LCD_SS_GPIO_Port,LCD_SS_Pin,GPIO_PIN_SET);
  HAL_SPI_Transmit(&hspi4, (uint16_t *)test, 102, 100);
  HAL_GPIO_WritePin(LCD_SS_GPIO_Port,LCD_SS_Pin,GPIO_PIN_RESET);
  HAL_GPIO_WritePin(GPIOH,FRONT_LED_CTRL_Pin,GPIO_PIN_SET);
  HAL_Delay(5000);

  configureLEDDriver();
    setErrorLED(7,ON);
    HAL_Delay(1000);
    setErrorLED(7,OFF);
    setErrorLED(8,ON);
    HAL_Delay(1000);
    setErrorLED(8,OFF);
    setErrorLED(9,ON);
    HAL_Delay(1000);
    setErrorLED(8,ON);
    setErrorLED(9,ON);
    HAL_Delay(1000);
    setErrorLED(9,OFF);
    //int check = writeI2CRegister(LED.address,LED.led0_reg,blah2,1,1);
  //  if(check){
  //	  blah = readI2CRegister(LED.address,LED.led0_reg,1,1);
  //	  uartTransmitInt(blah[0],7);
  //  }
  //  else{
  //	  uartTransmitChar("Things didn't go well.\r\n",7);
  //  }

  /* USER CODE END 2 */

  /* Init scheduler */
  osKernelInitialize();

  /* Create the thread(s) */
  /* creation of Heartbeat */
  HeartbeatHandle = osThreadNew(startHeartbeat, NULL, &Heartbeat_attributes);

  /* creation of adcRead */
  adcReadHandle = osThreadNew(startADCRead, NULL, &adcRead_attributes);

  /* creation of DatScreenBlink */
  DatScreenBlinkHandle = osThreadNew(GetDaScreenBlink, NULL, &DatScreenBlink_attributes);

  /* creation of Navigation */
  NavigationHandle = osThreadNew(navigation_control, NULL, &Navigation_attributes);

  /* Start scheduler */
  osKernelStart();

  /* We should never get here as control is now taken by the scheduler */
  /* Infinite loop */
  /* USER CODE BEGIN WHILE */

  while (1)
  {
	  HAL_Delay(1000);
	  if (!x) {
		  HAL_GPIO_WritePin(GPIOI,MCU_HEARTBEAT_Pin,GPIO_PIN_SET);
		  x=1;

		  //uartTransmitChar("hello\r\n",7);
		  HAL_GPIO_WritePin(LCD_SS_GPIO_Port,LCD_SS_Pin,GPIO_PIN_SET);
		  HAL_SPI_Transmit(&hspi4, (uint16_t *)&LCD_Blink_White, 1, 100);
		  HAL_GPIO_WritePin(LCD_SS_GPIO_Port,LCD_SS_Pin,GPIO_PIN_RESET);
	  }
	  else{
		  HAL_GPIO_WritePin(GPIOI,MCU_HEARTBEAT_Pin,GPIO_PIN_RESET);
		  x=0;
		  //uartTransmitChar("here\r\n",7);
		  HAL_GPIO_WritePin(LCD_SS_GPIO_Port,LCD_SS_Pin,GPIO_PIN_SET);
		  HAL_SPI_Transmit(&hspi4, (uint16_t *)&LCD_Blink_Black, 1, 100);
		  HAL_GPIO_WritePin(LCD_SS_GPIO_Port,LCD_SS_Pin,GPIO_PIN_RESET);
	  }
    /* USER CODE END WHILE */

  }
}

void SystemClock_Config(void)
{
  RCC_OscInitTypeDef RCC_OscInitStruct = {0};
  RCC_ClkInitTypeDef RCC_ClkInitStruct = {0};
  RCC_PeriphCLKInitTypeDef PeriphClkInitStruct = {0};

  /** Configure LSE Drive Capability
  */
  HAL_PWR_EnableBkUpAccess();
  __HAL_RCC_LSEDRIVE_CONFIG(RCC_LSEDRIVE_LOW);
  /** Configure the main internal regulator output voltage
  */
  __HAL_RCC_PWR_CLK_ENABLE();
  __HAL_PWR_VOLTAGESCALING_CONFIG(PWR_REGULATOR_VOLTAGE_SCALE3);
  /** Initializes the RCC Oscillators according to the specified parameters
  * in the RCC_OscInitTypeDef structure.
  */
  RCC_OscInitStruct.OscillatorType = RCC_OSCILLATORTYPE_HSE|RCC_OSCILLATORTYPE_LSE;
  RCC_OscInitStruct.HSEState = RCC_HSE_ON;
  RCC_OscInitStruct.LSEState = RCC_LSE_ON;
  RCC_OscInitStruct.PLL.PLLState = RCC_PLL_ON;
  RCC_OscInitStruct.PLL.PLLSource = RCC_PLLSOURCE_HSE;
  RCC_OscInitStruct.PLL.PLLM = 15;
  RCC_OscInitStruct.PLL.PLLN = 144;
  RCC_OscInitStruct.PLL.PLLP = RCC_PLLP_DIV2;
  RCC_OscInitStruct.PLL.PLLQ = 5;
  if (HAL_RCC_OscConfig(&RCC_OscInitStruct) != HAL_OK)
  {
    Error_Handler();
  }
  /** Initializes the CPU, AHB and APB buses clocks
  */
  RCC_ClkInitStruct.ClockType = RCC_CLOCKTYPE_HCLK|RCC_CLOCKTYPE_SYSCLK
                              |RCC_CLOCKTYPE_PCLK1|RCC_CLOCKTYPE_PCLK2;
  RCC_ClkInitStruct.SYSCLKSource = RCC_SYSCLKSOURCE_HSE;
  RCC_ClkInitStruct.AHBCLKDivider = RCC_SYSCLK_DIV1;
  RCC_ClkInitStruct.APB1CLKDivider = RCC_HCLK_DIV1;
  RCC_ClkInitStruct.APB2CLKDivider = RCC_HCLK_DIV16;

  if (HAL_RCC_ClockConfig(&RCC_ClkInitStruct, FLASH_LATENCY_0) != HAL_OK)
  {
    Error_Handler();
  }
  PeriphClkInitStruct.PeriphClockSelection = RCC_PERIPHCLK_RTC|RCC_PERIPHCLK_UART4
                              |RCC_PERIPHCLK_UART5|RCC_PERIPHCLK_UART7
                              |RCC_PERIPHCLK_I2C1|RCC_PERIPHCLK_I2C2
                              |RCC_PERIPHCLK_I2C3|RCC_PERIPHCLK_I2C4
                              |RCC_PERIPHCLK_CLK48;
  PeriphClkInitStruct.RTCClockSelection = RCC_RTCCLKSOURCE_LSE;
  PeriphClkInitStruct.Uart4ClockSelection = RCC_UART4CLKSOURCE_PCLK1;
  PeriphClkInitStruct.Uart5ClockSelection = RCC_UART5CLKSOURCE_PCLK1;
  PeriphClkInitStruct.Uart7ClockSelection = RCC_UART7CLKSOURCE_PCLK1;
  PeriphClkInitStruct.I2c1ClockSelection = RCC_I2C1CLKSOURCE_PCLK1;
  PeriphClkInitStruct.I2c2ClockSelection = RCC_I2C2CLKSOURCE_PCLK1;
  PeriphClkInitStruct.I2c3ClockSelection = RCC_I2C3CLKSOURCE_PCLK1;
  PeriphClkInitStruct.I2c4ClockSelection = RCC_I2C4CLKSOURCE_PCLK1;
  PeriphClkInitStruct.Clk48ClockSelection = RCC_CLK48SOURCE_PLL;
  if (HAL_RCCEx_PeriphCLKConfig(&PeriphClkInitStruct) != HAL_OK)
  {
    Error_Handler();
  }
}

/**
  * @brief NVIC Configuration.
  * @retval None
  */
static void MX_NVIC_Init(void)
{
  /* EXTI9_5_IRQn interrupt configuration */
  HAL_NVIC_SetPriority(EXTI9_5_IRQn, 5, 0);
  HAL_NVIC_EnableIRQ(EXTI9_5_IRQn);
  /* EXTI4_IRQn interrupt configuration */
  HAL_NVIC_SetPriority(EXTI4_IRQn, 5, 0);
  HAL_NVIC_EnableIRQ(EXTI4_IRQn);
}

static void MX_ADC1_Init(void)
{

  ADC_ChannelConfTypeDef sConfig = {0};

  /** Configure the global features of the ADC (Clock, Resolution, Data Alignment and number of conversion)
  */
  hadc1.Instance = ADC1;
  hadc1.Init.ClockPrescaler = ADC_CLOCK_SYNC_PCLK_DIV2;
  hadc1.Init.Resolution = ADC_RESOLUTION_12B;
  hadc1.Init.ScanConvMode = ADC_SCAN_ENABLE;
  hadc1.Init.ContinuousConvMode = ENABLE;
  hadc1.Init.DiscontinuousConvMode = DISABLE;
  hadc1.Init.ExternalTrigConvEdge = ADC_EXTERNALTRIGCONVEDGE_NONE;
  hadc1.Init.ExternalTrigConv = ADC_SOFTWARE_START;
  hadc1.Init.DataAlign = ADC_DATAALIGN_RIGHT;
  hadc1.Init.NbrOfConversion = 11;
  hadc1.Init.DMAContinuousRequests = ENABLE;
  hadc1.Init.EOCSelection = ADC_EOC_SINGLE_CONV;
  if (HAL_ADC_Init(&hadc1) != HAL_OK)
  {
    Error_Handler();
  }
  /** Configure for the selected ADC regular channel its corresponding rank in the sequencer and its sample time.
  */
  sConfig.Channel = ADC_CHANNEL_3;
  sConfig.Rank = ADC_REGULAR_RANK_1;
  sConfig.SamplingTime = ADC_SAMPLETIME_480CYCLES;
  if (HAL_ADC_ConfigChannel(&hadc1, &sConfig) != HAL_OK)
  {
    Error_Handler();
  }
  /** Configure for the selected ADC regular channel its corresponding rank in the sequencer and its sample time.
  */
  sConfig.Channel = ADC_CHANNEL_4;
  sConfig.Rank = ADC_REGULAR_RANK_2;
  if (HAL_ADC_ConfigChannel(&hadc1, &sConfig) != HAL_OK)
  {
    Error_Handler();
  }
  /** Configure for the selected ADC regular channel its corresponding rank in the sequencer and its sample time.
  */
  sConfig.Channel = ADC_CHANNEL_5;
  sConfig.Rank = ADC_REGULAR_RANK_3;
  if (HAL_ADC_ConfigChannel(&hadc1, &sConfig) != HAL_OK)
  {
    Error_Handler();
  }
  /** Configure for the selected ADC regular channel its corresponding rank in the sequencer and its sample time.
  */
  sConfig.Channel = ADC_CHANNEL_6;
  sConfig.Rank = ADC_REGULAR_RANK_4;
  if (HAL_ADC_ConfigChannel(&hadc1, &sConfig) != HAL_OK)
  {
    Error_Handler();
  }
  /** Configure for the selected ADC regular channel its corresponding rank in the sequencer and its sample time.
  */
  sConfig.Channel = ADC_CHANNEL_7;
  sConfig.Rank = ADC_REGULAR_RANK_5;
  if (HAL_ADC_ConfigChannel(&hadc1, &sConfig) != HAL_OK)
  {
    Error_Handler();
  }
  /** Configure for the selected ADC regular channel its corresponding rank in the sequencer and its sample time.
  */
  sConfig.Channel = ADC_CHANNEL_8;
  sConfig.Rank = ADC_REGULAR_RANK_6;
  if (HAL_ADC_ConfigChannel(&hadc1, &sConfig) != HAL_OK)
  {
    Error_Handler();
  }
  /** Configure for the selected ADC regular channel its corresponding rank in the sequencer and its sample time.
  */
  sConfig.Channel = ADC_CHANNEL_9;
  sConfig.Rank = ADC_REGULAR_RANK_7;
  if (HAL_ADC_ConfigChannel(&hadc1, &sConfig) != HAL_OK)
  {
    Error_Handler();
  }
  /** Configure for the selected ADC regular channel its corresponding rank in the sequencer and its sample time.
  */
  sConfig.Channel = ADC_CHANNEL_10;
  sConfig.Rank = ADC_REGULAR_RANK_8;
  if (HAL_ADC_ConfigChannel(&hadc1, &sConfig) != HAL_OK)
  {
    Error_Handler();
  }
  /** Configure for the selected ADC regular channel its corresponding rank in the sequencer and its sample time.
  */
  sConfig.Channel = ADC_CHANNEL_11;
  sConfig.Rank = ADC_REGULAR_RANK_9;
  if (HAL_ADC_ConfigChannel(&hadc1, &sConfig) != HAL_OK)
  {
    Error_Handler();
  }
  /** Configure for the selected ADC regular channel its corresponding rank in the sequencer and its sample time.
  */
  sConfig.Channel = ADC_CHANNEL_12;
  sConfig.Rank = ADC_REGULAR_RANK_10;
  if (HAL_ADC_ConfigChannel(&hadc1, &sConfig) != HAL_OK)
  {
    Error_Handler();
  }
  /** Configure for the selected ADC regular channel its corresponding rank in the sequencer and its sample time.
  */
  sConfig.Channel = ADC_CHANNEL_13;
  sConfig.Rank = ADC_REGULAR_RANK_11;
  if (HAL_ADC_ConfigChannel(&hadc1, &sConfig) != HAL_OK)
  {
    Error_Handler();
  }

}

static void MX_ADC2_Init(void)
{

  ADC_ChannelConfTypeDef sConfig = {0};

  /** Configure the global features of the ADC (Clock, Resolution, Data Alignment and number of conversion)
  */
  hadc2.Instance = ADC2;
  hadc2.Init.ClockPrescaler = ADC_CLOCK_SYNC_PCLK_DIV2;
  hadc2.Init.Resolution = ADC_RESOLUTION_12B;
  hadc2.Init.ScanConvMode = ADC_SCAN_ENABLE;
  hadc2.Init.ContinuousConvMode = ENABLE;
  hadc2.Init.DiscontinuousConvMode = DISABLE;
  hadc2.Init.ExternalTrigConvEdge = ADC_EXTERNALTRIGCONVEDGE_NONE;
  hadc2.Init.ExternalTrigConv = ADC_SOFTWARE_START;
  hadc2.Init.DataAlign = ADC_DATAALIGN_RIGHT;
  hadc2.Init.NbrOfConversion = 4;
  hadc2.Init.DMAContinuousRequests = ENABLE;
  hadc2.Init.EOCSelection = ADC_EOC_SINGLE_CONV;
  if (HAL_ADC_Init(&hadc2) != HAL_OK)
  {
    Error_Handler();
  }
  /** Configure for the selected ADC regular channel its corresponding rank in the sequencer and its sample time.
  */
  sConfig.Channel = ADC_CHANNEL_0;
  sConfig.Rank = ADC_REGULAR_RANK_1;
  sConfig.SamplingTime = ADC_SAMPLETIME_480CYCLES;
  if (HAL_ADC_ConfigChannel(&hadc2, &sConfig) != HAL_OK)
  {
    Error_Handler();
  }
  /** Configure for the selected ADC regular channel its corresponding rank in the sequencer and its sample time.
  */
  sConfig.Channel = ADC_CHANNEL_1;
  sConfig.Rank = ADC_REGULAR_RANK_2;
  if (HAL_ADC_ConfigChannel(&hadc2, &sConfig) != HAL_OK)
  {
    Error_Handler();
  }
  /** Configure for the selected ADC regular channel its corresponding rank in the sequencer and its sample time.
  */
  sConfig.Channel = ADC_CHANNEL_14;
  sConfig.Rank = ADC_REGULAR_RANK_3;
  if (HAL_ADC_ConfigChannel(&hadc2, &sConfig) != HAL_OK)
  {
    Error_Handler();
  }
  /** Configure for the selected ADC regular channel its corresponding rank in the sequencer and its sample time.
  */
  sConfig.Channel = ADC_CHANNEL_15;
  sConfig.Rank = ADC_REGULAR_RANK_4;
  if (HAL_ADC_ConfigChannel(&hadc2, &sConfig) != HAL_OK)
  {
    Error_Handler();
  }

}

static void MX_ADC3_Init(void)
{

  ADC_ChannelConfTypeDef sConfig = {0};

  /** Configure the global features of the ADC (Clock, Resolution, Data Alignment and number of conversion)
  */
  hadc3.Instance = ADC3;
  hadc3.Init.ClockPrescaler = ADC_CLOCK_SYNC_PCLK_DIV2;
  hadc3.Init.Resolution = ADC_RESOLUTION_12B;
  hadc3.Init.ScanConvMode = ADC_SCAN_ENABLE;
  hadc3.Init.ContinuousConvMode = ENABLE;
  hadc3.Init.DiscontinuousConvMode = DISABLE;
  hadc3.Init.ExternalTrigConvEdge = ADC_EXTERNALTRIGCONVEDGE_NONE;
  hadc3.Init.ExternalTrigConv = ADC_SOFTWARE_START;
  hadc3.Init.DataAlign = ADC_DATAALIGN_RIGHT;
  hadc3.Init.NbrOfConversion = 6;
  hadc3.Init.DMAContinuousRequests = ENABLE;
  hadc3.Init.EOCSelection = ADC_EOC_SINGLE_CONV;
  if (HAL_ADC_Init(&hadc3) != HAL_OK)
  {
    Error_Handler();
  }
  /** Configure for the selected ADC regular channel its corresponding rank in the sequencer and its sample time.
  */
  sConfig.Channel = ADC_CHANNEL_2;
  sConfig.Rank = ADC_REGULAR_RANK_1;
  sConfig.SamplingTime = ADC_SAMPLETIME_480CYCLES;
  if (HAL_ADC_ConfigChannel(&hadc3, &sConfig) != HAL_OK)
  {
    Error_Handler();
  }
  /** Configure for the selected ADC regular channel its corresponding rank in the sequencer and its sample time.
  */
  sConfig.Channel = ADC_CHANNEL_4;
  sConfig.Rank = ADC_REGULAR_RANK_2;
  if (HAL_ADC_ConfigChannel(&hadc3, &sConfig) != HAL_OK)
  {
    Error_Handler();
  }
  /** Configure for the selected ADC regular channel its corresponding rank in the sequencer and its sample time.
  */
  sConfig.Channel = ADC_CHANNEL_5;
  sConfig.Rank = ADC_REGULAR_RANK_3;
  if (HAL_ADC_ConfigChannel(&hadc3, &sConfig) != HAL_OK)
  {
    Error_Handler();
  }
  /** Configure for the selected ADC regular channel its corresponding rank in the sequencer and its sample time.
  */
  sConfig.Channel = ADC_CHANNEL_6;
  sConfig.Rank = ADC_REGULAR_RANK_4;
  if (HAL_ADC_ConfigChannel(&hadc3, &sConfig) != HAL_OK)
  {
    Error_Handler();
  }
  /** Configure for the selected ADC regular channel its corresponding rank in the sequencer and its sample time.
  */
  sConfig.Channel = ADC_CHANNEL_7;
  sConfig.Rank = ADC_REGULAR_RANK_5;
  if (HAL_ADC_ConfigChannel(&hadc3, &sConfig) != HAL_OK)
  {
    Error_Handler();
  }
  /** Configure for the selected ADC regular channel its corresponding rank in the sequencer and its sample time.
  */
  sConfig.Channel = ADC_CHANNEL_8;
  sConfig.Rank = ADC_REGULAR_RANK_6;
  if (HAL_ADC_ConfigChannel(&hadc3, &sConfig) != HAL_OK)
  {
    Error_Handler();
  }

}

static void MX_DAC_Init(void)
{

  DAC_ChannelConfTypeDef sConfig = {0};

  /** DAC Initialization
  */
  hdac.Instance = DAC;
  if (HAL_DAC_Init(&hdac) != HAL_OK)
  {
    Error_Handler();
  }
  /** DAC channel OUT1 config
  */
  sConfig.DAC_Trigger = DAC_TRIGGER_NONE;
  sConfig.DAC_OutputBuffer = DAC_OUTPUTBUFFER_ENABLE;
  if (HAL_DAC_ConfigChannel(&hdac, &sConfig, DAC_CHANNEL_1) != HAL_OK)
  {
    Error_Handler();
  }
  /** DAC channel OUT2 config
  */
  if (HAL_DAC_ConfigChannel(&hdac, &sConfig, DAC_CHANNEL_2) != HAL_OK)
  {
    Error_Handler();
  }

}

static void MX_I2C1_Init(void)
{

  hi2c1.Instance = I2C1;
  hi2c1.Init.Timing = 0x00606092;
  hi2c1.Init.OwnAddress1 = 0;
  hi2c1.Init.AddressingMode = I2C_ADDRESSINGMODE_7BIT;
  hi2c1.Init.DualAddressMode = I2C_DUALADDRESS_DISABLE;
  hi2c1.Init.OwnAddress2 = 0;
  hi2c1.Init.OwnAddress2Masks = I2C_OA2_NOMASK;
  hi2c1.Init.GeneralCallMode = I2C_GENERALCALL_DISABLE;
  hi2c1.Init.NoStretchMode = I2C_NOSTRETCH_DISABLE;
  if (HAL_I2C_Init(&hi2c1) != HAL_OK)
  {
    Error_Handler();
  }
  /** Configure Analogue filter
  */
  if (HAL_I2CEx_ConfigAnalogFilter(&hi2c1, I2C_ANALOGFILTER_ENABLE) != HAL_OK)
  {
    Error_Handler();
  }
  /** Configure Digital filter
  */
  if (HAL_I2CEx_ConfigDigitalFilter(&hi2c1, 0) != HAL_OK)
  {
    Error_Handler();
  }

}

static void MX_I2C2_Init(void)
{

  hi2c2.Instance = I2C2;
  hi2c2.Init.Timing = 0x00606092;
  hi2c2.Init.OwnAddress1 = 0;
  hi2c2.Init.AddressingMode = I2C_ADDRESSINGMODE_7BIT;
  hi2c2.Init.DualAddressMode = I2C_DUALADDRESS_DISABLE;
  hi2c2.Init.OwnAddress2 = 0;
  hi2c2.Init.OwnAddress2Masks = I2C_OA2_NOMASK;
  hi2c2.Init.GeneralCallMode = I2C_GENERALCALL_DISABLE;
  hi2c2.Init.NoStretchMode = I2C_NOSTRETCH_DISABLE;
  if (HAL_I2C_Init(&hi2c2) != HAL_OK)
  {
    Error_Handler();
  }
  /** Configure Analogue filter
  */
  if (HAL_I2CEx_ConfigAnalogFilter(&hi2c2, I2C_ANALOGFILTER_ENABLE) != HAL_OK)
  {
    Error_Handler();
  }
  /** Configure Digital filter
  */
  if (HAL_I2CEx_ConfigDigitalFilter(&hi2c2, 0) != HAL_OK)
  {
    Error_Handler();
  }

}

static void MX_I2C3_Init(void)
{

  hi2c3.Instance = I2C3;
  hi2c3.Init.Timing = 0x00606092;
  hi2c3.Init.OwnAddress1 = 0;
  hi2c3.Init.AddressingMode = I2C_ADDRESSINGMODE_7BIT;
  hi2c3.Init.DualAddressMode = I2C_DUALADDRESS_DISABLE;
  hi2c3.Init.OwnAddress2 = 0;
  hi2c3.Init.OwnAddress2Masks = I2C_OA2_NOMASK;
  hi2c3.Init.GeneralCallMode = I2C_GENERALCALL_DISABLE;
  hi2c3.Init.NoStretchMode = I2C_NOSTRETCH_DISABLE;
  if (HAL_I2C_Init(&hi2c3) != HAL_OK)
  {
    Error_Handler();
  }
  /** Configure Analogue filter
  */
  if (HAL_I2CEx_ConfigAnalogFilter(&hi2c3, I2C_ANALOGFILTER_ENABLE) != HAL_OK)
  {
    Error_Handler();
  }
  /** Configure Digital filter
  */
  if (HAL_I2CEx_ConfigDigitalFilter(&hi2c3, 0) != HAL_OK)
  {
    Error_Handler();
  }

}

static void MX_I2C4_Init(void)
{

  hi2c4.Instance = I2C4;
  hi2c4.Init.Timing = 0x00606092;
  hi2c4.Init.OwnAddress1 = 0;
  hi2c4.Init.AddressingMode = I2C_ADDRESSINGMODE_7BIT;
  hi2c4.Init.DualAddressMode = I2C_DUALADDRESS_DISABLE;
  hi2c4.Init.OwnAddress2 = 0;
  hi2c4.Init.OwnAddress2Masks = I2C_OA2_NOMASK;
  hi2c4.Init.GeneralCallMode = I2C_GENERALCALL_DISABLE;
  hi2c4.Init.NoStretchMode = I2C_NOSTRETCH_DISABLE;
  if (HAL_I2C_Init(&hi2c4) != HAL_OK)
  {
    Error_Handler();
  }
  /** Configure Analogue filter
  */
  if (HAL_I2CEx_ConfigAnalogFilter(&hi2c4, I2C_ANALOGFILTER_ENABLE) != HAL_OK)
  {
    Error_Handler();
  }
  /** Configure Digital filter
  */
  if (HAL_I2CEx_ConfigDigitalFilter(&hi2c4, 0) != HAL_OK)
  {
    Error_Handler();
  }

}

static void MX_RTC_Init(void)
{

  RTC_TimeTypeDef sTime = {0};
  RTC_DateTypeDef sDate = {0};

  /** Initialize RTC Only
  */
  hrtc.Instance = RTC;
  hrtc.Init.HourFormat = RTC_HOURFORMAT_24;
  hrtc.Init.AsynchPrediv = 127;
  hrtc.Init.SynchPrediv = 255;
  hrtc.Init.OutPut = RTC_OUTPUT_DISABLE;
  hrtc.Init.OutPutPolarity = RTC_OUTPUT_POLARITY_HIGH;
  hrtc.Init.OutPutType = RTC_OUTPUT_TYPE_OPENDRAIN;
  if (HAL_RTC_Init(&hrtc) != HAL_OK)
  {
    Error_Handler();
  }

  /** Initialize RTC and set the Time and Date
  */
  sTime.Hours = 0x0;
  sTime.Minutes = 0x0;
  sTime.Seconds = 0x0;
  sTime.DayLightSaving = RTC_DAYLIGHTSAVING_NONE;
  sTime.StoreOperation = RTC_STOREOPERATION_RESET;
  if (HAL_RTC_SetTime(&hrtc, &sTime, RTC_FORMAT_BCD) != HAL_OK)
  {
    Error_Handler();
  }
  sDate.WeekDay = RTC_WEEKDAY_MONDAY;
  sDate.Month = RTC_MONTH_JANUARY;
  sDate.Date = 0x1;
  sDate.Year = 0x0;

  if (HAL_RTC_SetDate(&hrtc, &sDate, RTC_FORMAT_BCD) != HAL_OK)
  {
    Error_Handler();
  }

}

static void MX_SPI4_Init(void)
{

  /* SPI4 parameter configuration*/
  hspi4.Instance = SPI4;
  hspi4.Init.Mode = SPI_MODE_MASTER;
  hspi4.Init.Direction = SPI_DIRECTION_2LINES;
  hspi4.Init.DataSize = SPI_DATASIZE_16BIT;
  hspi4.Init.CLKPolarity = SPI_POLARITY_LOW;
  hspi4.Init.CLKPhase = SPI_PHASE_1EDGE;
  hspi4.Init.NSS = SPI_NSS_SOFT;
  hspi4.Init.BaudRatePrescaler = SPI_BAUDRATEPRESCALER_16;
  hspi4.Init.FirstBit = SPI_FIRSTBIT_MSB;
  hspi4.Init.TIMode = SPI_TIMODE_DISABLE;
  hspi4.Init.CRCCalculation = SPI_CRCCALCULATION_DISABLE;
  hspi4.Init.CRCPolynomial = 7;
  hspi4.Init.CRCLength = SPI_CRC_LENGTH_DATASIZE;
  hspi4.Init.NSSPMode = SPI_NSS_PULSE_DISABLE;
  if (HAL_SPI_Init(&hspi4) != HAL_OK)
  {
    Error_Handler();
  }

}

static void MX_SPI5_Init(void)
{

  /* SPI5 parameter configuration*/
  hspi5.Instance = SPI5;
  hspi5.Init.Mode = SPI_MODE_MASTER;
  hspi5.Init.Direction = SPI_DIRECTION_2LINES;
  hspi5.Init.DataSize = SPI_DATASIZE_8BIT;
  hspi5.Init.CLKPolarity = SPI_POLARITY_LOW;
  hspi5.Init.CLKPhase = SPI_PHASE_1EDGE;
  hspi5.Init.NSS = SPI_NSS_HARD_OUTPUT;
  hspi5.Init.BaudRatePrescaler = SPI_BAUDRATEPRESCALER_16;
  hspi5.Init.FirstBit = SPI_FIRSTBIT_MSB;
  hspi5.Init.TIMode = SPI_TIMODE_DISABLE;
  hspi5.Init.CRCCalculation = SPI_CRCCALCULATION_DISABLE;
  hspi5.Init.CRCPolynomial = 7;
  hspi5.Init.CRCLength = SPI_CRC_LENGTH_DATASIZE;
  hspi5.Init.NSSPMode = SPI_NSS_PULSE_DISABLE;
  if (HAL_SPI_Init(&hspi5) != HAL_OK)
  {
    Error_Handler();
  }

}

static void MX_TIM4_Init(void)
{

  TIM_ClockConfigTypeDef sClockSourceConfig = {0};
  TIM_MasterConfigTypeDef sMasterConfig = {0};
  TIM_OC_InitTypeDef sConfigOC = {0};

  htim4.Instance = TIM4;
  htim4.Init.Prescaler = 0;
  htim4.Init.CounterMode = TIM_COUNTERMODE_UP;
  htim4.Init.Period = 65535;
  htim4.Init.ClockDivision = TIM_CLOCKDIVISION_DIV1;
  htim4.Init.AutoReloadPreload = TIM_AUTORELOAD_PRELOAD_DISABLE;
  if (HAL_TIM_Base_Init(&htim4) != HAL_OK)
  {
    Error_Handler();
  }
  sClockSourceConfig.ClockSource = TIM_CLOCKSOURCE_INTERNAL;
  if (HAL_TIM_ConfigClockSource(&htim4, &sClockSourceConfig) != HAL_OK)
  {
    Error_Handler();
  }
  if (HAL_TIM_PWM_Init(&htim4) != HAL_OK)
  {
    Error_Handler();
  }
  sMasterConfig.MasterOutputTrigger = TIM_TRGO_RESET;
  sMasterConfig.MasterSlaveMode = TIM_MASTERSLAVEMODE_DISABLE;
  if (HAL_TIMEx_MasterConfigSynchronization(&htim4, &sMasterConfig) != HAL_OK)
  {
    Error_Handler();
  }
  sConfigOC.OCMode = TIM_OCMODE_PWM1;
  sConfigOC.Pulse = 0;
  sConfigOC.OCPolarity = TIM_OCPOLARITY_HIGH;
  sConfigOC.OCFastMode = TIM_OCFAST_DISABLE;
  if (HAL_TIM_PWM_ConfigChannel(&htim4, &sConfigOC, TIM_CHANNEL_1) != HAL_OK)
  {
    Error_Handler();
  }
  HAL_TIM_MspPostInit(&htim4);

}

static void MX_TIM5_Init(void)
{

  TIM_ClockConfigTypeDef sClockSourceConfig = {0};
  TIM_MasterConfigTypeDef sMasterConfig = {0};
  TIM_OC_InitTypeDef sConfigOC = {0};

  htim5.Instance = TIM5;
  htim5.Init.Prescaler = 0;
  htim5.Init.CounterMode = TIM_COUNTERMODE_UP;
  htim5.Init.Period = 4294967295;
  htim5.Init.ClockDivision = TIM_CLOCKDIVISION_DIV1;
  htim5.Init.AutoReloadPreload = TIM_AUTORELOAD_PRELOAD_DISABLE;
  if (HAL_TIM_Base_Init(&htim5) != HAL_OK)
  {
    Error_Handler();
  }
  sClockSourceConfig.ClockSource = TIM_CLOCKSOURCE_INTERNAL;
  if (HAL_TIM_ConfigClockSource(&htim5, &sClockSourceConfig) != HAL_OK)
  {
    Error_Handler();
  }
  if (HAL_TIM_PWM_Init(&htim5) != HAL_OK)
  {
    Error_Handler();
  }
  sMasterConfig.MasterOutputTrigger = TIM_TRGO_RESET;
  sMasterConfig.MasterSlaveMode = TIM_MASTERSLAVEMODE_DISABLE;
  if (HAL_TIMEx_MasterConfigSynchronization(&htim5, &sMasterConfig) != HAL_OK)
  {
    Error_Handler();
  }
  sConfigOC.OCMode = TIM_OCMODE_PWM1;
  sConfigOC.Pulse = 0;
  sConfigOC.OCPolarity = TIM_OCPOLARITY_HIGH;
  sConfigOC.OCFastMode = TIM_OCFAST_DISABLE;
  if (HAL_TIM_PWM_ConfigChannel(&htim5, &sConfigOC, TIM_CHANNEL_1) != HAL_OK)
  {
    Error_Handler();
  }
  if (HAL_TIM_PWM_ConfigChannel(&htim5, &sConfigOC, TIM_CHANNEL_2) != HAL_OK)
  {
    Error_Handler();
  }
  HAL_TIM_MspPostInit(&htim5);

}

static void MX_UART4_Init(void)
{

  huart4.Instance = UART4;
  huart4.Init.BaudRate = 115200;
  huart4.Init.WordLength = UART_WORDLENGTH_8B;
  huart4.Init.StopBits = UART_STOPBITS_1;
  huart4.Init.Parity = UART_PARITY_NONE;
  huart4.Init.Mode = UART_MODE_TX_RX;
  huart4.Init.HwFlowCtl = UART_HWCONTROL_NONE;
  huart4.Init.OverSampling = UART_OVERSAMPLING_16;
  huart4.Init.OneBitSampling = UART_ONE_BIT_SAMPLE_DISABLE;
  huart4.AdvancedInit.AdvFeatureInit = UART_ADVFEATURE_NO_INIT;
  if (HAL_UART_Init(&huart4) != HAL_OK)
  {
    Error_Handler();
  }

}

static void MX_UART5_Init(void)
{

  huart5.Instance = UART5;
  huart5.Init.BaudRate = 115200;
  huart5.Init.WordLength = UART_WORDLENGTH_8B;
  huart5.Init.StopBits = UART_STOPBITS_1;
  huart5.Init.Parity = UART_PARITY_NONE;
  huart5.Init.Mode = UART_MODE_TX_RX;
  huart5.Init.HwFlowCtl = UART_HWCONTROL_NONE;
  huart5.Init.OverSampling = UART_OVERSAMPLING_16;
  huart5.Init.OneBitSampling = UART_ONE_BIT_SAMPLE_DISABLE;
  huart5.AdvancedInit.AdvFeatureInit = UART_ADVFEATURE_NO_INIT;
  if (HAL_UART_Init(&huart5) != HAL_OK)
  {
    Error_Handler();
  }

}

static void MX_UART7_Init(void)
{

  huart7.Instance = UART7;
  huart7.Init.BaudRate = 115200;
  huart7.Init.WordLength = UART_WORDLENGTH_8B;
  huart7.Init.StopBits = UART_STOPBITS_1;
  huart7.Init.Parity = UART_PARITY_NONE;
  huart7.Init.Mode = UART_MODE_TX_RX;
  huart7.Init.HwFlowCtl = UART_HWCONTROL_RTS_CTS;
  huart7.Init.OverSampling = UART_OVERSAMPLING_16;
  huart7.Init.OneBitSampling = UART_ONE_BIT_SAMPLE_DISABLE;
  huart7.AdvancedInit.AdvFeatureInit = UART_ADVFEATURE_NO_INIT;
  if (HAL_UART_Init(&huart7) != HAL_OK)
  {
    Error_Handler();
  }

}

static void MX_USB_OTG_FS_PCD_Init(void)
{

  hpcd_USB_OTG_FS.Instance = USB_OTG_FS;
  hpcd_USB_OTG_FS.Init.dev_endpoints = 6;
  hpcd_USB_OTG_FS.Init.speed = PCD_SPEED_FULL;
  hpcd_USB_OTG_FS.Init.dma_enable = DISABLE;
  hpcd_USB_OTG_FS.Init.phy_itface = PCD_PHY_EMBEDDED;
  hpcd_USB_OTG_FS.Init.Sof_enable = DISABLE;
  hpcd_USB_OTG_FS.Init.low_power_enable = DISABLE;
  hpcd_USB_OTG_FS.Init.lpm_enable = DISABLE;
  hpcd_USB_OTG_FS.Init.vbus_sensing_enable = DISABLE;
  hpcd_USB_OTG_FS.Init.use_dedicated_ep1 = DISABLE;
  if (HAL_PCD_Init(&hpcd_USB_OTG_FS) != HAL_OK)
  {
    Error_Handler();
  }

}

static void MX_DMA_Init(void)
{

  /* DMA controller clock enable */
  __HAL_RCC_DMA2_CLK_ENABLE();
  __HAL_RCC_DMA1_CLK_ENABLE();

  /* DMA interrupt init */
  /* DMA1_Stream0_IRQn interrupt configuration */
  HAL_NVIC_SetPriority(DMA1_Stream0_IRQn, 5, 0);
  HAL_NVIC_EnableIRQ(DMA1_Stream0_IRQn);
  /* DMA2_Stream0_IRQn interrupt configuration */
  HAL_NVIC_SetPriority(DMA2_Stream0_IRQn, 5, 0);
  HAL_NVIC_EnableIRQ(DMA2_Stream0_IRQn);
  /* DMA2_Stream1_IRQn interrupt configuration */
  HAL_NVIC_SetPriority(DMA2_Stream1_IRQn, 5, 0);
  HAL_NVIC_EnableIRQ(DMA2_Stream1_IRQn);
  /* DMA2_Stream2_IRQn interrupt configuration */
  HAL_NVIC_SetPriority(DMA2_Stream2_IRQn, 5, 0);
  HAL_NVIC_EnableIRQ(DMA2_Stream2_IRQn);

}

static void MX_GPIO_Init(void)
{
  GPIO_InitTypeDef GPIO_InitStruct = {0};

  /* GPIO Ports Clock Enable */
  __HAL_RCC_GPIOE_CLK_ENABLE();
  __HAL_RCC_GPIOG_CLK_ENABLE();
  __HAL_RCC_GPIOB_CLK_ENABLE();
  __HAL_RCC_GPIOC_CLK_ENABLE();
  __HAL_RCC_GPIOA_CLK_ENABLE();
  __HAL_RCC_GPIOI_CLK_ENABLE();
  __HAL_RCC_GPIOK_CLK_ENABLE();
  __HAL_RCC_GPIOF_CLK_ENABLE();
  __HAL_RCC_GPIOD_CLK_ENABLE();
  __HAL_RCC_GPIOH_CLK_ENABLE();
  __HAL_RCC_GPIOJ_CLK_ENABLE();

  /*Configure GPIO pin Output Level */
  HAL_GPIO_WritePin(LCD_SS_GPIO_Port, LCD_SS_Pin, GPIO_PIN_RESET);

  /*Configure GPIO pin Output Level */
  HAL_GPIO_WritePin(GPIOG, OUT3_1V8_Pin|OUT1_1V8_Pin|OUT1_OD_Pin|OUT0_OD_Pin
                          |OUT0_1V8_Pin|OUT2_1V8_Pin, GPIO_PIN_RESET);

  /*Configure GPIO pin Output Level */
  HAL_GPIO_WritePin(GPIOI, OUT3_CONFIG_Pin|OUT1_CONFIG_Pin|OUT2_CONFIG_Pin|MCU_HEARTBEAT_Pin, GPIO_PIN_RESET);

  /*Configure GPIO pin Output Level */
  HAL_GPIO_WritePin(GPIOK, MCU_CTRL2_Pin|MCU_CTRL1_Pin, GPIO_PIN_RESET);

  /*Configure GPIO pin Output Level */
  HAL_GPIO_WritePin(GPIOF, BTN0_Pin|BTN1_Pin|BTN2_Pin|BTN3_Pin
                          |BTN4_Pin|BTN5_Pin, GPIO_PIN_RESET);

  /*Configure GPIO pin Output Level */
  HAL_GPIO_WritePin(GPIOH, OUT0_CONFIG_Pin|FRONT_LED_CTRL_Pin, GPIO_PIN_RESET);

  /*Configure GPIO pin Output Level */
  HAL_GPIO_WritePin(GPIOB, ZION_PWR_EN_Pin|EDL_EN_Pin|SPARE_SW_EN_Pin, GPIO_PIN_RESET);

  /*Configure GPIO pin Output Level */
  HAL_GPIO_WritePin(GPIOJ, MCU_CTRL0_Pin|UART_MUX_CTRL_Pin|LCD_EXTMODE_Pin|LCD_DISP_Pin, GPIO_PIN_RESET);

  /*Configure GPIO pin : LCD_SS_Pin */
  GPIO_InitStruct.Pin = LCD_SS_Pin;
  GPIO_InitStruct.Mode = GPIO_MODE_OUTPUT_PP;
  GPIO_InitStruct.Pull = GPIO_NOPULL;
  GPIO_InitStruct.Speed = GPIO_SPEED_FREQ_HIGH;
  HAL_GPIO_Init(LCD_SS_GPIO_Port, &GPIO_InitStruct);

  /*Configure GPIO pin : UI_INPUT11_Pin */
  GPIO_InitStruct.Pin = UI_INPUT11_Pin;
  GPIO_InitStruct.Mode = GPIO_MODE_INPUT;
  GPIO_InitStruct.Pull = GPIO_NOPULL;
  HAL_GPIO_Init(UI_INPUT11_GPIO_Port, &GPIO_InitStruct);

  /*Configure GPIO pins : OUT3_1V8_Pin OUT1_1V8_Pin OUT1_OD_Pin OUT0_OD_Pin
                           OUT0_1V8_Pin OUT2_1V8_Pin */
  GPIO_InitStruct.Pin = OUT3_1V8_Pin|OUT1_1V8_Pin|OUT1_OD_Pin|OUT0_OD_Pin
                          |OUT0_1V8_Pin|OUT2_1V8_Pin;
  GPIO_InitStruct.Mode = GPIO_MODE_OUTPUT_PP;
  GPIO_InitStruct.Pull = GPIO_NOPULL;
  GPIO_InitStruct.Speed = GPIO_SPEED_FREQ_LOW;
  HAL_GPIO_Init(GPIOG, &GPIO_InitStruct);

  /*Configure GPIO pin : UI_INPUT0_Pin */
  GPIO_InitStruct.Pin = UI_INPUT0_Pin;
  GPIO_InitStruct.Mode = GPIO_MODE_INPUT;
  GPIO_InitStruct.Pull = GPIO_NOPULL;
  HAL_GPIO_Init(UI_INPUT0_GPIO_Port, &GPIO_InitStruct);

  /*Configure GPIO pins : OUT3_CONFIG_Pin OUT1_CONFIG_Pin OUT2_CONFIG_Pin MCU_HEARTBEAT_Pin */
  GPIO_InitStruct.Pin = OUT3_CONFIG_Pin|OUT1_CONFIG_Pin|OUT2_CONFIG_Pin|MCU_HEARTBEAT_Pin;
  GPIO_InitStruct.Mode = GPIO_MODE_OUTPUT_PP;
  GPIO_InitStruct.Pull = GPIO_NOPULL;
  GPIO_InitStruct.Speed = GPIO_SPEED_FREQ_LOW;
  HAL_GPIO_Init(GPIOI, &GPIO_InitStruct);

  /*Configure GPIO pins : DWN_BTN_Pin SEL_BTN_Pin UP_BTN_Pin BCK_BTN_Pin */
  GPIO_InitStruct.Pin = DWN_BTN_Pin|SEL_BTN_Pin|UP_BTN_Pin|BCK_BTN_Pin;
  GPIO_InitStruct.Mode = GPIO_MODE_IT_FALLING;
  GPIO_InitStruct.Pull = GPIO_NOPULL;
  HAL_GPIO_Init(GPIOK, &GPIO_InitStruct);

  /*Configure GPIO pin : UI_INPUT1_Pin */
  GPIO_InitStruct.Pin = UI_INPUT1_Pin;
  GPIO_InitStruct.Mode = GPIO_MODE_INPUT;
  GPIO_InitStruct.Pull = GPIO_NOPULL;
  HAL_GPIO_Init(UI_INPUT1_GPIO_Port, &GPIO_InitStruct);

  /*Configure GPIO pins : UI_INPUT2_Pin UI_INPUT10_Pin UI_INPUT5_Pin UI_INPUT9_Pin
                           UI_INPUT4_Pin UI_INPUT3_Pin UI_INPUT7_Pin UI_INPUT8_Pin
                           UI_INPUT6_Pin */
  GPIO_InitStruct.Pin = UI_INPUT2_Pin|UI_INPUT10_Pin|UI_INPUT5_Pin|UI_INPUT9_Pin
                          |UI_INPUT4_Pin|UI_INPUT3_Pin|UI_INPUT7_Pin|UI_INPUT8_Pin
                          |UI_INPUT6_Pin;
  GPIO_InitStruct.Mode = GPIO_MODE_INPUT;
  GPIO_InitStruct.Pull = GPIO_NOPULL;
  HAL_GPIO_Init(GPIOD, &GPIO_InitStruct);

  /*Configure GPIO pins : MCU_CTRL2_Pin MCU_CTRL1_Pin */
  GPIO_InitStruct.Pin = MCU_CTRL2_Pin|MCU_CTRL1_Pin;
  GPIO_InitStruct.Mode = GPIO_MODE_OUTPUT_PP;
  GPIO_InitStruct.Pull = GPIO_NOPULL;
  GPIO_InitStruct.Speed = GPIO_SPEED_FREQ_LOW;
  HAL_GPIO_Init(GPIOK, &GPIO_InitStruct);

  /*Configure GPIO pins : BTN0_Pin BTN1_Pin BTN2_Pin BTN3_Pin
                           BTN4_Pin BTN5_Pin */
  GPIO_InitStruct.Pin = BTN0_Pin|BTN1_Pin|BTN2_Pin|BTN3_Pin
                          |BTN4_Pin|BTN5_Pin;
  GPIO_InitStruct.Mode = GPIO_MODE_OUTPUT_PP;
  GPIO_InitStruct.Pull = GPIO_NOPULL;
  GPIO_InitStruct.Speed = GPIO_SPEED_FREQ_LOW;
  HAL_GPIO_Init(GPIOF, &GPIO_InitStruct);

  /*Configure GPIO pins : OUT0_CONFIG_Pin FRONT_LED_CTRL_Pin */
  GPIO_InitStruct.Pin = OUT0_CONFIG_Pin|FRONT_LED_CTRL_Pin;
  GPIO_InitStruct.Mode = GPIO_MODE_OUTPUT_PP;
  GPIO_InitStruct.Pull = GPIO_NOPULL;
  GPIO_InitStruct.Speed = GPIO_SPEED_FREQ_LOW;
  HAL_GPIO_Init(GPIOH, &GPIO_InitStruct);

  /*Configure GPIO pins : ZION_PWR_EN_Pin EDL_EN_Pin SPARE_SW_EN_Pin */
  GPIO_InitStruct.Pin = ZION_PWR_EN_Pin|EDL_EN_Pin|SPARE_SW_EN_Pin;
  GPIO_InitStruct.Mode = GPIO_MODE_OUTPUT_PP;
  GPIO_InitStruct.Pull = GPIO_NOPULL;
  GPIO_InitStruct.Speed = GPIO_SPEED_FREQ_LOW;
  HAL_GPIO_Init(GPIOB, &GPIO_InitStruct);

  /*Configure GPIO pins : MCU_CTRL0_Pin UART_MUX_CTRL_Pin LCD_EXTMODE_Pin LCD_DISP_Pin */
  GPIO_InitStruct.Pin = MCU_CTRL0_Pin|UART_MUX_CTRL_Pin|LCD_EXTMODE_Pin|LCD_DISP_Pin;
  GPIO_InitStruct.Mode = GPIO_MODE_OUTPUT_PP;
  GPIO_InitStruct.Pull = GPIO_NOPULL;
  GPIO_InitStruct.Speed = GPIO_SPEED_FREQ_LOW;
  HAL_GPIO_Init(GPIOJ, &GPIO_InitStruct);

}

/* USER CODE BEGIN 4 */
int __io_putchar(int ch)
{
	HAL_UART_Transmit(&huart7, (uint8_t *)&ch, 1, 0xFFFF);

	return ch;
}

void uartTransmitChar(char *message, int uart){
	char uart_buf[200];
	int uart_buf_len;
	uart_buf_len = sprintf(uart_buf, message);
	if (uart =7){
		HAL_UART_Transmit(&huart7, (uint8_t *)uart_buf, uart_buf_len,100);
	}
}
void uartTransmitInt(uint16_t *number, int uart){
	char uart_buf[80];
	int uart_buf_len;
	uart_buf_len = sprintf(uart_buf, "0x%x\r\n", number);
	if (uart =7){
		HAL_UART_Transmit(&huart7, (uint8_t *)uart_buf, uart_buf_len,100);
	}

}

uint8_t * readI2CRegister(uint8_t address, uint8_t reg, int bytes, int i2CBank){
	static uint8_t buf[20];
	HAL_StatusTypeDef ret;
	buf[0]=reg;
  	if(i2CBank=1){
  		ret = HAL_I2C_Master_Transmit(&hi2c1, address, buf, 1, HAL_MAX_DELAY);
  	}
  	else if(i2CBank=2){
  		ret = HAL_I2C_Master_Transmit(&hi2c2, address, buf, 1, HAL_MAX_DELAY);
  	}
  	else if(i2CBank=3){
  		ret = HAL_I2C_Master_Transmit(&hi2c3, address, buf, 1, HAL_MAX_DELAY);
  	}
  	else if(i2CBank=4){
  		ret = HAL_I2C_Master_Transmit(&hi2c4, address, buf, 1, HAL_MAX_DELAY);
  	}
	  if ( ret != HAL_OK ) {
	          return 0xfe;
	        }
	  else {
		  if(i2CBank=1){
				ret = HAL_I2C_Master_Receive(&hi2c1, address, buf, bytes, HAL_MAX_DELAY);
			}
			else if(i2CBank=2){
				ret = HAL_I2C_Master_Receive(&hi2c2, address, buf, bytes, HAL_MAX_DELAY);
			}
			else if(i2CBank=3){
				ret = HAL_I2C_Master_Receive(&hi2c3, address, buf, bytes, HAL_MAX_DELAY);
			}
			else if(i2CBank=4){
				ret = HAL_I2C_Master_Receive(&hi2c4, address, buf, bytes, HAL_MAX_DELAY);
			}
		  if ( ret != HAL_OK ) {
		          return 0xfe;
		        }
		  else{
			  uartTransmitInt(buf[0],7);
			  return buf;
		  }
}
}
int writeI2CRegister(uint8_t address, uint8_t reg, uint8_t * bytes, int numBytes, int i2CBank){
	  	uint8_t buf[20];
	  	HAL_StatusTypeDef ret;
	  	buf[0]=reg;
	  	int x = 0;
	  	for (x=0;x<(sizeof(bytes)-1);x++){
	  		buf[1+x] = bytes[x];
	  	}
	  	if(i2CBank=1){
	  		ret = HAL_I2C_Master_Transmit(&hi2c1, address, buf, numBytes+1, HAL_MAX_DELAY);
	  	}
	  	else if(i2CBank=2){
	  		ret = HAL_I2C_Master_Transmit(&hi2c2, address, buf, numBytes+1, HAL_MAX_DELAY);
	  	}
	  	else if(i2CBank=3){
	  		ret = HAL_I2C_Master_Transmit(&hi2c3, address, buf, numBytes+1, HAL_MAX_DELAY);
	  	}
	  	else if(i2CBank=4){
	  		ret = HAL_I2C_Master_Transmit(&hi2c4, address, buf, numBytes+1, HAL_MAX_DELAY);
	  	}
	  	if ( ret != HAL_OK ) {
	  	          return 0;
	  	        }
	  	else {
	  		  return 1;
	  }
}
void configureLEDDriver(){
	uint8_t currentMultiplier = 0b00000001;
	static uint8_t* clear[1];
	clear[0]=0x0;
	uint8_t * buf;
	//reduce the current multiplier to set brightness lower. See if this works. If not, we can work with PWM.
	writeI2CRegister(LED.address, LED.iref_reg, currentMultiplier,1,LED.i2cBank);
	buf = readI2CRegister(LED.address,LED.iref_reg,1,LED.i2cBank);
	//Turn on oscillator. Must be turned on before LED driver functions
	writeI2CRegister(LED.address,LED.mode0_reg,LED.mode0_oscon_value,1,LED.i2cBank);
	//clear the default state of the led register.
	writeI2CRegister(LED.address,LED.led0_reg,clear,1,LED.i2cBank);
	writeI2CRegister(LED.address,LED.led1_reg,clear,1,LED.i2cBank);
	writeI2CRegister(LED.address,LED.led2_reg,clear,1,LED.i2cBank);
	writeI2CRegister(LED.address,LED.led3_reg,clear,1,LED.i2cBank);
	//set the PWM for the tri-color led. Thing is bright so PWM is very low.
	writeI2CRegister(LED.address,LED.led7_pwm,LED.pwm,1,LED.i2cBank);
	writeI2CRegister(LED.address,LED.led8_pwm,LED.pwm,1,LED.i2cBank);
	writeI2CRegister(LED.address,LED.led9_pwm,LED.pwm,1,LED.i2cBank);

}

//Configures specified LED to either fully on or off.
void setErrorLED(int led,_Bool change){
	const uint8_t led0 = 0b00000001;
	const uint8_t led1 = 0b00000100;
	const uint8_t led2 = 0b00010000;
	const uint8_t led3 = 0b01000000;
	const uint8_t led0_pwm = 0b00000010;
	const uint8_t led1_pwm = 0b00001000;
	const uint8_t led2_pwm = 0b00100000;
	const uint8_t led3_pwm = 0b10000000;
  	uint8_t* ledRegisterContents;
  	int ledBitNumber;
  	uint8_t ledRegister;
	if(led <4){
		ledRegister = LED.led0_reg;
		ledBitNumber=led;
	}
	else if(led <8){
		ledRegister = LED.led1_reg;
		ledBitNumber=led-4;
	}
	else if(led <12){
		ledRegister = LED.led2_reg;
		ledBitNumber=led-8;
	}
	else{ //put this in to humor those who want to try using unconnected LEDs
		ledRegister = LED.led3_reg;
		ledBitNumber=led-12;
	}
	ledRegisterContents = readI2CRegister(LED.address,ledRegister, 1, LED.i2cBank);
	switch(ledBitNumber){

	case 0:
		if(change){
			if(led = 8){
				ledRegisterContents[0] |= led0_pwm;
			}
			else{
				ledRegisterContents[0] |= led0;
			}
		}
		else{
			if(led = 8){
				ledRegisterContents[0] &= ~led0_pwm;
			}
			else{
				ledRegisterContents[0] &= ~led0;
			}
		}
		break;

	case 1:
		if(change){
			if(led = 9){
				ledRegisterContents[0] |= led1_pwm;
			}
			else{
				ledRegisterContents[0] |= led1;
			}
		}
		else{
			if(led = 9){
				ledRegisterContents[0] &= ~led1_pwm;
			}
			else{
				ledRegisterContents[0] &= ~led1;
			}
		}
		break;

	case 2:
		if(change){
				ledRegisterContents[0] |= led2;
		}
		else{

			ledRegisterContents[0] &= ~led2;
		}
		break;

	case 3:
		if(change){
			if(led = 7){
				ledRegisterContents[0] |= led3_pwm;
			}
			else{
				ledRegisterContents[0] |= led3;
			}
		}
		else{
			if(led = 7){
				ledRegisterContents[0] &= ~led3_pwm;
			}
			else{
				ledRegisterContents[0] &= ~led3;
			}
		}
		break;
	}
	writeI2CRegister(LED.address,ledRegister,ledRegisterContents,1,LED.i2cBank);
	ledRegisterContents = readI2CRegister(LED.address,ledRegister, 1, LED.i2cBank);
}

//// Called when first half of buffer is filled
//void HAL_ADC_ConvHalfCpltCallback(ADC_HandleTypeDef* hadc) {
//}
//
//// Called when buffer is completely filled
void HAL_ADC_ConvCpltCallback(ADC_HandleTypeDef* hadc) {
}
/* USER CODE END 4 */

void startHeartbeat(void *argument)
{
  /* USER CODE BEGIN 5 */
  /* Infinite loop */
  for(;;)
  {
	  //HAL_GPIO_TogglePin(GPIOI,MCU_HEARTBEAT_Pin);
	  osDelay(500);
  }

  /* USER CODE END 5 */
}

void startADCRead(void *argument)
{
  /* USER CODE BEGIN startADCRead */
  /* Infinite loop */
  for(;;)
  {
	  //empty out the data ready variables and the adc3_bufs
	memset(adcRestart,0,sizeof(adcRestart));
	memset(adc1_buf, 0, sizeof(adc1_buf));
	memset(adc2_buf, 0, sizeof(adc2_buf));
	memset(adc3_buf, 0, sizeof(adc3_buf));
	//restart the DMAs.
	HAL_ADC_Start_DMA(&hadc1, (uint32_t*)adc1_buf, ADC_BUF_LEN);
	HAL_ADC_Start_DMA(&hadc2, (uint32_t*)adc2_buf, ADC_BUF_LEN);
	HAL_ADC_Start_DMA(&hadc3, (uint32_t*)adc3_buf, ADC_BUF_LEN);
    osDelay(5000);
  }
  /* USER CODE END startADCRead */
}

void GetDaScreenBlink(void *argument)
{
  /* USER CODE BEGIN GetDaScreenBlink */
  /* Infinite loop */
	 static uint16_t LCD_Blink_White = 0b0001100000000000;
	 static uint16_t LCD_Blink_Black = 0b0001000000000000;
	 int x = 0;
	 uint32_t ulNotifiedValue;
	 uint8_t button_val = 0;
	 uint8_t menu_val = 0;
	 uint8_t running_menu = 0;

  for(;;)
  {
	  ulNotifiedValue = 0;
	  xTaskNotifyWait(NOTIFY_NOCLEAR, NOTIFY_CLEARALL, &ulNotifiedValue, portMAX_DELAY);
	  // button press decode
	  button_val = (ulNotifiedValue & NOTIFY_BTN_MASK);
	  menu_val = ((ulNotifiedValue & NOTIFY_MENU_MASK) >> NOTIFY_MENU_BIT);
	  running_menu = ((ulNotifiedValue & NOTIFY_RUN_MENU_MASK) >> NOTIFY_MENU_RUN_BIT);
//	  printf("uNotifiedValue %d\r\n", ulNotifiedValue);
//	  printf("running_menu: %d\r\n", running_menu);
//	  printf("highlighed menu: %d\n\r", menu_val);
//	  printf("button_press: %d\r\n", button_val);

	  // If the BACK button was pressed, just run the SEL button case with the previous menu
	  if (button_val == BACK)
	  {
		  button_val = SEL;
	  }

	  switch(button_val)
	  {
	  case UP:
	  {
		  // increment display indicator location on present menu
		  printf("switch UP\r\n");
		  //uartTransmitChar("switch UP\r\n",7);
		  HAL_GPIO_TogglePin(LCD_SS_GPIO_Port,LCD_SS_Pin);
		  HAL_SPI_Transmit(&hspi4, (uint16_t *)&LCD_Blink_White, 1, 100);
		  HAL_GPIO_TogglePin(LCD_SS_GPIO_Port,LCD_SS_Pin);
		  break;
	  }
	  case DWN:
	  {
		  // decrement display indicator location on present menu
		  printf("switch DWN\r\n");
		  //uartTransmitChar("switch DOWN\r\n",7);
		  HAL_GPIO_WritePin(LCD_SS_GPIO_Port,LCD_SS_Pin,GPIO_PIN_SET);
		  HAL_SPI_Transmit(&hspi4, (uint16_t *)&LCD_Blink_Black, 1, 100);
		  HAL_GPIO_WritePin(LCD_SS_GPIO_Port,LCD_SS_Pin,GPIO_PIN_RESET);
		  break;
	  }
	  case BACK:
	  {
		  // change display state or menu
		  printf("switch BACK\r\n");
		  //uartTransmitChar("switch BACK\r\n",7);
		  break;
	  }
	  case SEL:
	  {
		  // change display state or menu
		  printf("switch SEL\r\n");
		  //uartTransmitChar("switch SEL\r\n",7);
		  switch(running_menu)
		  {
		  case BOOT_MENU:
		  {
			  printf("BOOT_MENU\r\n");
			  //uartTransmitChar("switch BOOT_MENU\r\n",7);
			  HAL_GPIO_WritePin(LCD_SS_GPIO_Port,LCD_SS_Pin,GPIO_PIN_SET);
			  HAL_SPI_Transmit(&hspi4, (uint16_t *)&LCD_Blink_Black, 1, 100);
			  HAL_GPIO_WritePin(LCD_SS_GPIO_Port,LCD_SS_Pin,GPIO_PIN_RESET);
			  break;
		  }
		  case MAIN_MENU:
		  {
			  printf("MAIN_MENU\r\n");
			  //uartTransmitChar("switch MAIN_MENU\r\n",7);
			  HAL_GPIO_TogglePin(LCD_SS_GPIO_Port,LCD_SS_Pin);
			  HAL_SPI_Transmit(&hspi4, (uint16_t *)&LCD_Blink_White, 1, 100);
			  HAL_GPIO_TogglePin(LCD_SS_GPIO_Port,LCD_SS_Pin);
			  break;
		  }
		  case STATUS_MENU:
		  {
			  printf("STATUS_MENU\r\n");
			  //uartTransmitChar("switch STATUS_MENU\r\n",7);
			  HAL_GPIO_WritePin(LCD_SS_GPIO_Port,LCD_SS_Pin,GPIO_PIN_SET);
			  HAL_SPI_Transmit(&hspi4, (uint16_t *)&LCD_Blink_Black, 1, 100);
			  HAL_GPIO_WritePin(LCD_SS_GPIO_Port,LCD_SS_Pin,GPIO_PIN_RESET);
			  break;
		  }
		  case SYSTEM_INFO_MENU:
		  {
			  printf("SYSTEM INFO MENU\r\n");
			  //uartTransmitChar("switch SYSTEM INFO_MENU\r\n",7);
			  HAL_GPIO_TogglePin(LCD_SS_GPIO_Port,LCD_SS_Pin);
			  HAL_SPI_Transmit(&hspi4, (uint16_t *)&LCD_Blink_White, 1, 100);
			  HAL_GPIO_TogglePin(LCD_SS_GPIO_Port,LCD_SS_Pin);
			  break;
		  }
		  }
		  break;
	  }
	  default:
		  // no change in display indicator or state
		  //uartTransmitChar("switch NO BTN PRESS\r\n",7);
		  break;
	  }
//	 	  if (!x) {
//	 		  //HAL_GPIO_WritePin(GPIOI,MCU_HEARTBEAT_Pin,GPIO_PIN_SET);
//	 		  x=1;
//
//	 		  uartTransmitChar("hello\r\n",7);
//	 		  HAL_GPIO_TogglePin(LCD_SS_GPIO_Port,LCD_SS_Pin);
//	 		  HAL_SPI_Transmit(&hspi4, (uint16_t *)&LCD_Blink_White, 1, 100);
//	 		  HAL_GPIO_TogglePin(LCD_SS_GPIO_Port,LCD_SS_Pin);
//	 	  }
//	 	  else{
//	 		  //HAL_GPIO_WritePin(GPIOI,MCU_HEARTBEAT_Pin,GPIO_PIN_RESET);
//	 		  x=0;
//	 		  uartTransmitChar("here\r\n",7);
//	 		  HAL_GPIO_WritePin(LCD_SS_GPIO_Port,LCD_SS_Pin,GPIO_PIN_SET);
//	 		  HAL_SPI_Transmit(&hspi4, (uint16_t *)&LCD_Blink_Black, 1, 100);
//	 		  HAL_GPIO_WritePin(LCD_SS_GPIO_Port,LCD_SS_Pin,GPIO_PIN_RESET);
//	 	  }
	 	  osDelay(400);
  }
  /* USER CODE END GetDaScreenBlink */
}

void navigation_control(void *argument)
{
  /* USER CODE BEGIN navigation_control */
		uint8_t menu_highlight = MENU_TOP;	// variable indicates what menu item is currently being highlighted
		uint8_t	menu_run = BOOT_MENU;		// variable to track what menu is currently running
		uint8_t prev_menu = menu_run;		// variable to track what the previous menu running was, this is used for the BACK button
		//uint8_t button_press = 1;
		// Clear button flags here

	  /* Infinite loop */
	  for(;;)
	  {
		switch(inputButtonSet)
		{
		case UP:
		{
			if (menu_highlight == MENU_TOP)
			{
				//do nothing
			}
			else
			{
				menu_highlight = menu_highlight - 1;
				// task notify the display task with UP and current highlighted item
				// task notification U32 bits defined as:
				// [0:3]: menu button flags [0]:UP, [1]:DWN, [2]:SEL, [3]:Reserved
				// [4:7]: menu indicator highlight flags
				// [8:11]: currently running menu flags
				xTaskNotify(DatScreenBlinkHandle, (UP | (menu_highlight << NOTIFY_MENU_BIT) | (menu_run << NOTIFY_MENU_RUN_BIT)), eSetValueWithoutOverwrite);
			}
			break;
		}
		case DWN:
		{
			if (menu_highlight >= MAX_MENU_ITEMS)
			{
				//do nothing
			}
			else
			{
				menu_highlight = menu_highlight + 1;
				// task notify the display task with DWN and current highlighted item
				// task notification U32 bits defined as:
				// [0:3]: menu button flags [0]:UP, [1]:DWN, [2]:SEL, [3]:Reserved
				// [4:7]: menu selection flags
				// [8:11]: currently running menu flags
				// [12:15]: previously running menu flags
				xTaskNotify(DatScreenBlinkHandle, (DWN | (menu_highlight << NOTIFY_MENU_BIT) | (menu_run << NOTIFY_MENU_RUN_BIT)), eSetValueWithoutOverwrite);
			}
			break;
		}
		case BACK:
		{
			menu_run = prev_menu;
			// task notify the display task with SEL and what menu to run
			// task notification U32 bits defined as:
			// [0:3]: menu button flags [0]:UP, [1]:DWN, [2]:SEL, [3]:Reserved
			// [4:7]: menu selection flags
			// [8:11]: currently running menu flags
			// [12:15]: previously running menu flags
			xTaskNotify(DatScreenBlinkHandle, (BACK | (menu_highlight << NOTIFY_MENU_BIT) | (menu_run << NOTIFY_MENU_RUN_BIT)), eSetValueWithoutOverwrite);
			break;
		}
		case SEL:
		{
			prev_menu = menu_run;		// save currently running menu for BACK button
			menu_run = menu_highlight;	// update the currently running menu to what the user SELECTED
//			printf("menu_run: %d\r\n", menu_run);
//			printf("prev_menu: %d\r\n", prev_menu);
//			printf("menu_run_adjust: %d\r\n", (menu_run << NOTIFY_MENU_RUN_BIT));
			// task notify the display task with SEL and what menu to run
			// task notification U32 bits defined as:
			// [0:3]: menu button flags [0]:UP, [1]:DWN, [2]:SEL, [3]:Reserved
			// [4:7]: menu selection flags
			// [8:11]: currently running menu flags
			// [12:15]: previously running menu flags
			xTaskNotify(DatScreenBlinkHandle, (SEL | (menu_highlight << NOTIFY_MENU_BIT) | (menu_run << NOTIFY_MENU_RUN_BIT)), eSetValueWithoutOverwrite);
			break;
		}
		default:
			// task notify the display task with no button press.  Just refresh the current running menu.
			xTaskNotify(DatScreenBlinkHandle, (NO_BTN_PRESS | (menu_highlight << NOTIFY_MENU_BIT) | (menu_run << NOTIFY_MENU_RUN_BIT)), eSetValueWithoutOverwrite);
			break;
		}
		inputButtonSet = NO_BTN_PRESS;
	    osDelay(700);
	  }

  /* USER CODE END navigation_control */
}

 /**
  * @brief  Period elapsed callback in non blocking mode
  * @note   This function is called  when TIM6 interrupt took place, inside
  * HAL_TIM_IRQHandler(). It makes a direct call to HAL_IncTick() to increment
  * a global variable "uwTick" used as application time base.
  * @param  htim : TIM handle
  * @retval None
  */
void HAL_TIM_PeriodElapsedCallback(TIM_HandleTypeDef *htim)
{
  if (htim->Instance == TIM6) {
    HAL_IncTick();
  }
}

void Error_Handler(void)
{
  __disable_irq();
  while (1)
  {
  }
}

/************************ (C) COPYRIGHT STMicroelectronics *****END OF FILE****/
